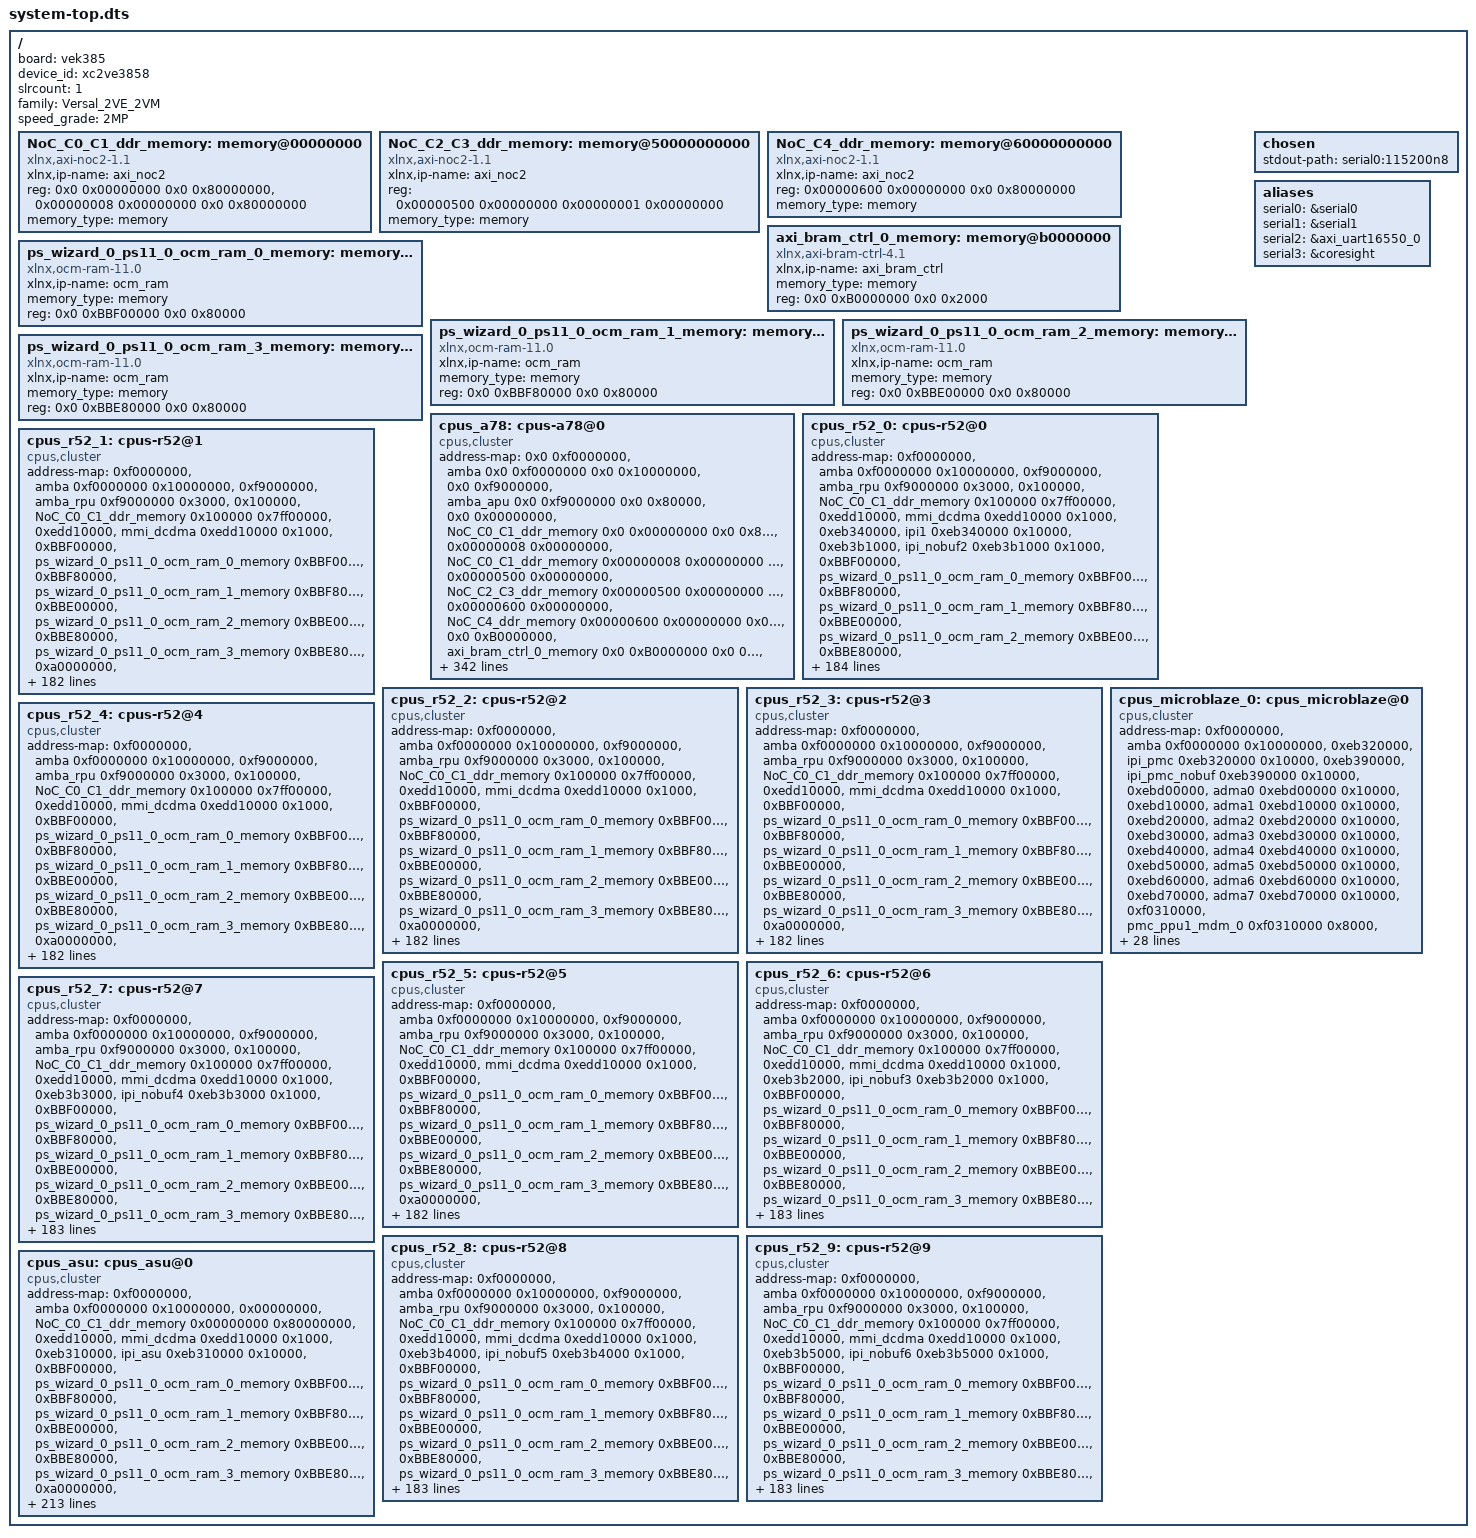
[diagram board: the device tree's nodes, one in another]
/dts-v1/;
#include "versal2.dtsi"
#include "versal2-clk-ccf.dtsi"
#include "pl.dtsi"
#include "pcw.dtsi"
/ {
	board = "vek385";
	device_id = "xc2ve3858";
	slrcount = <1>;
	family = "Versal_2VE_2VM";
	speed_grade = "2MP";
	NoC_C0_C1_ddr_memory: memory@00000000 {
		compatible = "xlnx,axi-noc2-1.1";
		xlnx,ip-name = "axi_noc2";
		device_type = "memory";
		reg = <0x0 0x00000000 0x0 0x80000000>, <0x00000008 0x00000000 0x0 0x80000000>;
		memory_type = "memory";
	};
	NoC_C2_C3_ddr_memory: memory@50000000000 {
		compatible = "xlnx,axi-noc2-1.1";
		xlnx,ip-name = "axi_noc2";
		device_type = "memory";
		reg = <0x00000500 0x00000000 0x00000001 0x00000000>;
		memory_type = "memory";
	};
	NoC_C4_ddr_memory: memory@60000000000 {
		compatible = "xlnx,axi-noc2-1.1";
		xlnx,ip-name = "axi_noc2";
		device_type = "memory";
		reg = <0x00000600 0x00000000 0x0 0x80000000>;
		memory_type = "memory";
	};
	axi_bram_ctrl_0_memory: memory@b0000000 {
		compatible = "xlnx,axi-bram-ctrl-4.1";
		xlnx,ip-name = "axi_bram_ctrl";
		device_type = "memory";
		memory_type = "memory";
		reg = <0x0 0xB0000000 0x0 0x2000>;
	};
	ps_wizard_0_ps11_0_ocm_ram_0_memory: memory@BBF00000 {
		compatible = "xlnx,ocm-ram-11.0" , "mmio-sram";
		xlnx,ip-name = "ocm_ram";
		device_type = "memory";
		memory_type = "memory";
		reg = <0x0 0xBBF00000 0x0 0x80000>;
	};
	ps_wizard_0_ps11_0_ocm_ram_1_memory: memory@BBF80000 {
		compatible = "xlnx,ocm-ram-11.0" , "mmio-sram";
		xlnx,ip-name = "ocm_ram";
		device_type = "memory";
		memory_type = "memory";
		reg = <0x0 0xBBF80000 0x0 0x80000>;
	};
	ps_wizard_0_ps11_0_ocm_ram_2_memory: memory@BBE00000 {
		compatible = "xlnx,ocm-ram-11.0" , "mmio-sram";
		xlnx,ip-name = "ocm_ram";
		device_type = "memory";
		memory_type = "memory";
		reg = <0x0 0xBBE00000 0x0 0x80000>;
	};
	ps_wizard_0_ps11_0_ocm_ram_3_memory: memory@BBE80000 {
		compatible = "xlnx,ocm-ram-11.0" , "mmio-sram";
		xlnx,ip-name = "ocm_ram";
		device_type = "memory";
		memory_type = "memory";
		reg = <0x0 0xBBE80000 0x0 0x80000>;
	};
	chosen {
		stdout-path = "serial0:115200n8";
	};
	aliases {
		serial0 = &serial0;
		serial1 = &serial1;
		serial2 = &axi_uart16550_0;
		serial3 = &coresight;
	};
	cpus_a78: cpus-a78@0 {
		compatible = "cpus,cluster";
		address-map = <0x0 0xf0000000 &amba 0x0 0xf0000000 0x0 0x10000000>, 
			      <0x0 0xf9000000 &amba_apu 0x0 0xf9000000 0x0 0x80000>, 
			      <0x0 0x00000000 &NoC_C0_C1_ddr_memory 0x0 0x00000000 0x0 0x80000000>, 
			      <0x00000008 0x00000000 &NoC_C0_C1_ddr_memory 0x00000008 0x00000000 0x0 0x80000000>, 
			      <0x00000500 0x00000000 &NoC_C2_C3_ddr_memory 0x00000500 0x00000000 0x00000001 0x00000000>, 
			      <0x00000600 0x00000000 &NoC_C4_ddr_memory 0x00000600 0x00000000 0x0 0x80000000>, 
			      <0x0 0xB0000000 &axi_bram_ctrl_0_memory 0x0 0xB0000000 0x0 0x2000>, 
			      <0x0 0xB0000000 &axi_bram_ctrl_0 0x0 0xB0000000 0x0 0x2000>, 
			      <0x0 0xedd10000 &mmi_dcdma 0x0 0xedd10000 0x0 0x1000>, 
			      <0x0 0xeb330000 &ipi0 0x0 0xeb330000 0x0 0x10000>, 
			      <0x0 0xeb3b0000 &ipi_nobuf1 0x0 0xeb3b0000 0x0 0x1000>, 
			      <0x0 0xeb350000 &ipi2 0x0 0xeb350000 0x0 0x10000>, 
			      <0x0 0xeb360000 &ipi3 0x0 0xeb360000 0x0 0x10000>, 
			      <0x0 0xeb370000 &ipi4 0x0 0xeb370000 0x0 0x10000>, 
			      <0x0 0xeb380000 &ipi5 0x0 0xeb380000 0x0 0x10000>, 
			      <0x0 0xeb3a0000 &ipi6 0x0 0xeb3a0000 0x0 0x10000>, 
			      <0x0 0xBBF00000 &ps_wizard_0_ps11_0_ocm_ram_0_memory 0x0 0xBBF00000 0x0 0x80000>, 
			      <0x0 0xBBF80000 &ps_wizard_0_ps11_0_ocm_ram_1_memory 0x0 0xBBF80000 0x0 0x80000>, 
			      <0x0 0xBBE00000 &ps_wizard_0_ps11_0_ocm_ram_2_memory 0x0 0xBBE00000 0x0 0x80000>, 
			      <0x0 0xBBE80000 &ps_wizard_0_ps11_0_ocm_ram_3_memory 0x0 0xBBE80000 0x0 0x80000>, 
			      <0x0 0xa0000000 &ps_wizard_0_ps11_0_noc_pcie_0 0x0 0xa0000000 0x0 0x10000000>, 
			      <0x0 0xa0000000 &ps_wizard_0_mmi_0_mmi_pcie_region_0 0x0 0xa0000000 0x0 0x10000000>, 
			      <0x0 0xb2000000 &axi_uart16550_0 0x0 0xb2000000 0x0 0x10000>, 
			      <0x0 0xb2010000 &pl_mmi_clk_wiz 0x0 0xb2010000 0x0 0x10000>, 
			      <0x0 0xb2020000 &axi_gpio_0 0x0 0xb2020000 0x0 0x10000>, 
			      <0x0 0xb2030000 &axi_gpio_1 0x0 0xb2030000 0x0 0x10000>, 
			      <0x0 0xb2040000 &axi_gpio_2 0x0 0xb2040000 0x0 0x10000>, 
			      <0x0 0xb2050000 &board_misc_gpios_board_misc_i2c1_alt_in 0x0 0xb2050000 0x0 0x10000>, 
			      <0x0 0xb2060000 &board_misc_gpios_board_misc_pcie_ep 0x0 0xb2060000 0x0 0x10000>, 
			      <0x0 0xb2070000 &board_misc_gpios_board_misc_pl_io_l16p 0x0 0xb2070000 0x0 0x10000>, 
			      <0x0 0xb2080000 &board_misc_gpios_board_misc_sc_gpio_in 0x0 0xb2080000 0x0 0x10000>, 
			      <0x0 0xb2090000 &board_misc_gpios_board_misc_sc_gpio_out 0x0 0xb2090000 0x0 0x10000>, 
			      <0x0 0xe2000000 &gic_a78 0x0 0xe2000000 0x0 0x400000>, 
			      <0x0 0xea460000 &ps_wizard_0_ps11_0_lpd_systmr_read 0x0 0xea460000 0x0 0x10000>, 
			      <0x0 0xea470000 &ps_wizard_0_ps11_0_lpd_systmr_ctrl 0x0 0xea470000 0x0 0x10000>, 
			      <0x0 0xeaa00000 &ps_wizard_0_ps11_0_ocm_ctrl_3 0x0 0xeaa00000 0x0 0x10000>, 
			      <0x0 0xeb400000 &ps_wizard_0_ps11_0_ocm_xmpu_0 0x0 0xeb400000 0x0 0x10000>, 
			      <0x0 0xeb410000 &ps_wizard_0_ps11_0_lpd_slcr_0 0x0 0xeb410000 0x0 0x100000>, 
			      <0x0 0xeb510000 &ps_wizard_0_ps11_0_lpd_slcr_secure_0 0x0 0xeb510000 0x0 0x40000>, 
			      <0x0 0xeb580000 &ps_wizard_0_ps11_0_rpu_a 0x0 0xeb580000 0x0 0x8000>, 
			      <0x0 0xeb590000 &ps_wizard_0_ps11_0_rpu_b 0x0 0xeb590000 0x0 0x8000>, 
			      <0x0 0xeb5d0000 &ps_wizard_0_ps11_0_ocm_ctrl_0 0x0 0xeb5d0000 0x0 0x10000>, 
			      <0x0 0xeb5e0000 &ps_wizard_0_ps11_0_crl_0 0x0 0xeb5e0000 0x0 0x300000>, 
			      <0x0 0xeb960000 &ps_wizard_0_ps11_0_ocm_ctrl_1 0x0 0xeb960000 0x0 0x10000>, 
			      <0x0 0xeb980000 &ps_wizard_0_ps11_0_ocm_xmpu_1 0x0 0xeb980000 0x0 0x10000>, 
			      <0x0 0xeb990000 &ps_wizard_0_ps11_0_lpd_xppu_0 0x0 0xeb990000 0x0 0x10000>, 
			      <0x0 0xeb9b0000 &ps_wizard_0_ps11_0_lpd_afi_0 0x0 0xeb9b0000 0x0 0x10000>, 
			      <0x0 0xeb9d0000 &ps_wizard_0_ps11_0_ocm_ctrl_2 0x0 0xeb9d0000 0x0 0x10000>, 
			      <0x0 0xeba00000 &r52_0a_atcm_global 0x0 0xeba00000 0x0 0x10000>, 
			      <0x0 0xeba10000 &r52_0a_btcm_global 0x0 0xeba10000 0x0 0x8000>, 
			      <0x0 0xeba20000 &r52_0a_ctcm_global 0x0 0xeba20000 0x0 0x8000>, 
			      <0x0 0xeba40000 &r52_1a_atcm_global 0x0 0xeba40000 0x0 0x10000>, 
			      <0x0 0xeba50000 &r52_1a_btcm_global 0x0 0xeba50000 0x0 0x8000>, 
			      <0x0 0xeba60000 &r52_1a_ctcm_global 0x0 0xeba60000 0x0 0x8000>, 
			      <0x0 0xeba80000 &r52_0b_atcm_global 0x0 0xeba80000 0x0 0x10000>, 
			      <0x0 0xeba90000 &r52_0b_btcm_global 0x0 0xeba90000 0x0 0x8000>, 
			      <0x0 0xebaa0000 &r52_0b_ctcm_global 0x0 0xebaa0000 0x0 0x8000>, 
			      <0x0 0xebac0000 &r52_1b_atcm_global 0x0 0xebac0000 0x0 0x10000>, 
			      <0x0 0xebad0000 &r52_1b_btcm_global 0x0 0xebad0000 0x0 0x8000>, 
			      <0x0 0xebae0000 &r52_1b_ctcm_global 0x0 0xebae0000 0x0 0x8000>, 
			      <0x0 0xebb00000 &r52_0c_atcm_global 0x0 0xebb00000 0x0 0x10000>, 
			      <0x0 0xebb10000 &r52_0c_btcm_global 0x0 0xebb10000 0x0 0x8000>, 
			      <0x0 0xebb20000 &r52_0c_ctcm_global 0x0 0xebb20000 0x0 0x8000>, 
			      <0x0 0xebb40000 &r52_1c_atcm_global 0x0 0xebb40000 0x0 0x10000>, 
			      <0x0 0xebb50000 &r52_1c_btcm_global 0x0 0xebb50000 0x0 0x8000>, 
			      <0x0 0xebb60000 &r52_1c_ctcm_global 0x0 0xebb60000 0x0 0x8000>, 
			      <0x0 0xebb80000 &r52_0d_atcm_global 0x0 0xebb80000 0x0 0x10000>, 
			      <0x0 0xebb90000 &r52_0d_btcm_global 0x0 0xebb90000 0x0 0x8000>, 
			      <0x0 0xebba0000 &r52_0d_ctcm_global 0x0 0xebba0000 0x0 0x8000>, 
			      <0x0 0xebbc0000 &r52_1d_atcm_global 0x0 0xebbc0000 0x0 0x10000>, 
			      <0x0 0xebbd0000 &r52_1d_btcm_global 0x0 0xebbd0000 0x0 0x8000>, 
			      <0x0 0xebbe0000 &r52_1d_ctcm_global 0x0 0xebbe0000 0x0 0x8000>, 
			      <0x0 0xebc00000 &r52_0e_atcm_global 0x0 0xebc00000 0x0 0x10000>, 
			      <0x0 0xebc10000 &r52_0e_btcm_global 0x0 0xebc10000 0x0 0x8000>, 
			      <0x0 0xebc20000 &r52_0e_ctcm_global 0x0 0xebc20000 0x0 0x8000>, 
			      <0x0 0xebc40000 &r52_1e_atcm_global 0x0 0xebc40000 0x0 0x10000>, 
			      <0x0 0xebc50000 &r52_1e_btcm_global 0x0 0xebc50000 0x0 0x8000>, 
			      <0x0 0xebc60000 &r52_1e_ctcm_global 0x0 0xebc60000 0x0 0x8000>, 
			      <0x0 0xebd00000 &adma0 0x0 0xebd00000 0x0 0x10000>, 
			      <0x0 0xebd10000 &adma1 0x0 0xebd10000 0x0 0x10000>, 
			      <0x0 0xebd20000 &adma2 0x0 0xebd20000 0x0 0x10000>, 
			      <0x0 0xebd30000 &adma3 0x0 0xebd30000 0x0 0x10000>, 
			      <0x0 0xebd40000 &adma4 0x0 0xebd40000 0x0 0x10000>, 
			      <0x0 0xebd50000 &adma5 0x0 0xebd50000 0x0 0x10000>, 
			      <0x0 0xebd60000 &adma6 0x0 0xebd60000 0x0 0x10000>, 
			      <0x0 0xebd70000 &adma7 0x0 0xebd70000 0x0 0x10000>, 
			      <0x0 0xebe8c000 &asu_dma0 0x0 0xebe8c000 0x0 0x1000>, 
			      <0x0 0xec200000 &ps_wizard_0_ps11_0_crf_0 0x0 0xec200000 0x0 0x100000>, 
			      <0x0 0xec810000 &ps_wizard_0_ps11_0_fpd_slv_asild_xmpu_0 0x0 0xec810000 0x0 0x10000>, 
			      <0x0 0xec820000 &ps_wizard_0_ps11_0_fpd_slv_asilb_xmpu_0 0x0 0xec820000 0x0 0x10000>, 
			      <0x0 0xec880000 &ps_wizard_0_ps11_0_fpd_afi_0 0x0 0xec880000 0x0 0x10000>, 
			      <0x0 0xec890000 &ps_wizard_0_ps11_0_fpd_afi_1 0x0 0xec890000 0x0 0x10000>, 
			      <0x0 0xec8a0000 &ps_wizard_0_ps11_0_fpd_afi_2 0x0 0xec8a0000 0x0 0x10000>, 
			      <0x0 0xec8b0000 &ps_wizard_0_ps11_0_fpd_afi_3 0x0 0xec8b0000 0x0 0x10000>, 
			      <0x0 0xec8c0000 &ps_wizard_0_ps11_0_fpd_slcr_0 0x0 0xec8c0000 0x0 0x10000>, 
			      <0x0 0xec8e0000 &ps_wizard_0_ps11_0_fpd_slcr_secure_0 0x0 0xec8e0000 0x0 0x10000>, 
			      <0x0 0xec910000 &ps_wizard_0_ps11_0_fpd_systmr_read 0x0 0xec910000 0x0 0x10000>, 
			      <0x0 0xec920000 &ps_wizard_0_ps11_0_fpd_systmr_ctrl 0x0 0xec920000 0x0 0x10000>, 
			      <0x0 0xecc00000 &ps_wizard_0_ps11_0_apu_0 0x0 0xecc00000 0x0 0x10000>, 
			      <0x0 0xecd00000 &ps_wizard_0_ps11_0_apu_1 0x0 0xecd00000 0x0 0x10000>, 
			      <0x0 0xece00000 &ps_wizard_0_ps11_0_apu_2 0x0 0xece00000 0x0 0x10000>, 
			      <0x0 0xecf00000 &ps_wizard_0_ps11_0_apu_3 0x0 0xecf00000 0x0 0x10000>, 
			      <0x0 0xed000000 &gpu 0x0 0xed000000 0x0 0x800000>, 
			      <0x0 0xed800000 &ps_wizard_0_mmi_0_mmi_pcie0 0x0 0xed800000 0x0 0x80000>, 
			      <0x0 0xed900000 &ps_wizard_0_mmi_0_mmi_gtyp_cfg 0x0 0xed900000 0x0 0x20000>, 
			      <0x0 0xed920000 &mmi_10gbe 0x0 0xed920000 0x0 0x10000>, 
			      <0x0 0xed930000 &ps_wizard_0_mmi_0_mmi_pipe_gem_slcr 0x0 0xed930000 0x0 0x1000>, 
			      <0x0 0xed931000 &mdb_pcie0 0x0 0xed931000 0x0 0x8000>, 
			      <0x0 0xeda00000 &ps_wizard_0_mmi_0_mmi_common 0x0 0xeda00000 0x0 0x300000>, 
			      <0x0 0xedd00000 &mmi_dc 0x0 0xedd00000 0x0 0x10000>, 
			      <0x0 0xedd10000 &ps_wizard_0_mmi_0_mmi_dpdma 0x0 0xedd10000 0x0 0x10000>, 
			      <0x0 0xede00000 &mmi_dptx 0x0 0xede00000 0x0 0x40000>, 
			      <0x0 0xede40000 &ps_wizard_0_mmi_0_mmi_usb3phy_crpara 0x0 0xede40000 0x0 0x40000>, 
			      <0x0 0xede80000 &ps_wizard_0_mmi_0_mmi_trng 0x0 0xede80000 0x0 0x10000>, 
			      <0x0 0xede90000 &ps_wizard_0_mmi_0_mmi_udh_pll 0x0 0xede90000 0x0 0x10000>, 
			      <0x0 0xedea0000 &ps_wizard_0_mmi_0_mmi_udh_slcr 0x0 0xedea0000 0x0 0x10000>, 
			      <0x0 0xedeb0000 &ps_wizard_0_mmi_0_mmi_hdcp 0x0 0xedeb0000 0x0 0x8000>, 
			      <0x0 0xedeb8000 &ps_wizard_0_mmi_0_mmi_usb3phy_tca 0x0 0xedeb8000 0x0 0x4000>, 
			      <0x0 0xedebc000 &ps_wizard_0_mmi_0_mmi_usb2phy 0x0 0xedebc000 0x0 0x4000>, 
			      <0x0 0xedec0000 &mmi_dwc3 0x0 0xedec0000 0x0 0x130000>, 
			      <0x0 0xf0310000 &pmc_ppu1_mdm_0 0x0 0xf0310000 0x0 0x8000>, 
			      <0x0 0xf0800000 &coresight 0x0 0xf0800000 0x0 0x4000>, 
			      <0x0 0xf08f0000 &ps_wizard_0_ps11_0_coresight_lpd_atm 0x0 0xf08f0000 0x0 0xf000>, 
			      <0x0 0xf0c40000 &ps_wizard_0_ps11_0_coresight_fpd_stm 0x0 0xf0c40000 0x0 0x4000>, 
			      <0x0 0xf1010000 &ospi 0x0 0xf1010000 0x0 0x10000>, 
			      <0x0 0xf1020000 &gpio1 0x0 0xf1020000 0x0 0x10000>, 
			      <0x0 0xf10a0000 &ps_wizard_0_ps11_0_pmc_ufs_0 0x0 0xf10a0000 0x0 0x10000>, 
			      <0x0 0xf10b0000 &ufshc 0x0 0xf10b0000 0x0 0x10000>, 
			      <0x0 0xf1110000 &ps_wizard_0_ps11_0_pmc_global_0 0x0 0xf1110000 0x0 0x50000>, 
			      <0x0 0xf11c0000 &dma0 0x0 0xf11c0000 0x0 0x10000>, 
			      <0x0 0xf11d0000 &dma1 0x0 0xf11d0000 0x0 0x10000>, 
			      <0x0 0xf11e0000 &ps_wizard_0_ps11_0_pmc_aes 0x0 0xf11e0000 0x0 0x10000>, 
			      <0x0 0xf11f0000 &ps_wizard_0_ps11_0_pmc_bbram_ctrl 0x0 0xf11f0000 0x0 0x10000>, 
			      <0x0 0xf1200000 &ps_wizard_0_ps11_0_pmc_rsa 0x0 0xf1200000 0x0 0x10000>, 
			      <0x0 0xf1210000 &ps_wizard_0_ps11_0_pmc_sha3 0x0 0xf1210000 0x0 0x10000>, 
			      <0x0 0xf1220000 &ps_wizard_0_ps11_0_pmc_slave_boot 0x0 0xf1220000 0x0 0x10000>, 
			      <0x0 0xf1220000 &ps_wizard_0_mmi_0_pmc_slave_boot 0x0 0xf1220000 0x0 0x10000>, 
			      <0x0 0xf1230000 &pmc_trng 0x0 0xf1230000 0x0 0x10000>, 
			      <0x0 0xf1240000 &ps_wizard_0_ps11_0_pmc_efuse_ctrl 0x0 0xf1240000 0x0 0x10000>, 
			      <0x0 0xf1250000 &ps_wizard_0_ps11_0_pmc_efuse_cache 0x0 0xf1250000 0x0 0x10000>, 
			      <0x0 0xf1260000 &ps_wizard_0_ps11_0_crp_0 0x0 0xf1260000 0x0 0x10000>, 
			      <0x0 0xf1270000 &sysmon0 0x0 0xf1270000 0x0 0x30000>, 
			      <0x0 0xf12a0000 &rtc 0x0 0xf12a0000 0x0 0x10000>, 
			      <0x0 0xf12b0000 &pmc_cfu_apb_0 0x0 0xf12b0000 0x0 0x10000>, 
			      <0x0 0xf12d0000 &pmc_cfi_cframe_0 0x0 0xf12d0000 0x0 0x1000>, 
			      <0x0 0xf12f0000 &ps_wizard_0_ps11_0_pmc_xmpu_0 0x0 0xf12f0000 0x0 0x10000>, 
			      <0x0 0xf1300000 &ps_wizard_0_ps11_0_pmc_xppu_npi_0 0x0 0xf1300000 0x0 0x10000>, 
			      <0x0 0xf1310000 &ps_wizard_0_ps11_0_pmc_xppu_0 0x0 0xf1310000 0x0 0x10000>, 
			      <0x0 0xf1800000 &ps_wizard_0_ps11_0_pmc_sha2 0x0 0xf1800000 0x0 0x10000>, 
			      <0x0 0xf1920000 &serial0 0x0 0xf1920000 0x0 0x10000>, 
			      <0x0 0xf1930000 &serial1 0x0 0xf1930000 0x0 0x10000>, 
			      <0x0 0xf1940000 &i2c0 0x0 0xf1940000 0x0 0x10000>, 
			      <0x0 0xf1950000 &i2c1 0x0 0xf1950000 0x0 0x10000>, 
			      <0x0 0xf19e0000 &can0 0x0 0xf19e0000 0x0 0x10000>, 
			      <0x0 0xf19f0000 &can1 0x0 0xf19f0000 0x0 0x10000>, 
			      <0x0 0xf1a00000 &can2 0x0 0xf1a00000 0x0 0x10000>, 
			      <0x0 0xf1a10000 &can3 0x0 0xf1a10000 0x0 0x10000>, 
			      <0x0 0xf1a20000 &ps_wizard_0_ps11_0_lpd_iou_slcr_0 0x0 0xf1a20000 0x0 0x20000>, 
			      <0x0 0xf1a40000 &ps_wizard_0_ps11_0_lpd_iou_secure_slcr_0 0x0 0xf1a40000 0x0 0x10000>, 
			      <0x0 0xf1a50000 &gpio0 0x0 0xf1a50000 0x0 0x10000>, 
			      <0x0 0xf1a60000 &gem0 0x0 0xf1a60000 0x0 0x10000>, 
			      <0x0 0xf1c00000 &dwc3_1 0x0 0xf1c00000 0x0 0x100000>, 
			      <0x0 0xf1e60000 &ttc0 0x0 0xf1e60000 0x0 0x10000>, 
			      <0x0 0xf1e70000 &ttc1 0x0 0xf1e70000 0x0 0x10000>, 
			      <0x0 0xf1e80000 &ttc2 0x0 0xf1e80000 0x0 0x10000>, 
			      <0x0 0xf1e90000 &ttc3 0x0 0xf1e90000 0x0 0x10000>, 
			      <0x0 0xf1ea0000 &ttc4 0x0 0xf1ea0000 0x0 0x10000>, 
			      <0x0 0xf1eb0000 &ttc5 0x0 0xf1eb0000 0x0 0x10000>, 
			      <0x0 0xf1ec0000 &ttc6 0x0 0xf1ec0000 0x0 0x10000>, 
			      <0x0 0xf1ed0000 &ttc7 0x0 0xf1ed0000 0x0 0x10000>, 
			      <0x0 0xf1ef0000 &usb1 0x0 0xf1ef0000 0x0 0x10000>, 
			      <0x0 0xf2100000 &ps_wizard_0_ps11_0_pmc_slave_boot_stream 0x0 0xf2100000 0x0 0x10000>, 
			      <0x0 0xf2100000 &ps_wizard_0_mmi_0_pmc_slave_boot_stream 0x0 0xf2100000 0x0 0x10000>, 
			      <0x0 0xf6000000 &ps_wizard_0_ps11_0_pmc_ram_npi 0x0 0xf6000000 0x0 0x2000000>, 
			      <0x0 0xf8000000 &ps_wizard_0_ps11_0_fpd_cmn 0x0 0xf8000000 0x0 0x4000000>, 
			      <0x00000200 0x00000000 &ai_engine_0 0x00000200 0x00000000 0x00000001 0x00000000>, 
			      <0x00001000 0x00000000 &ps_wizard_0_ps11_0_cpm_cdx_dpu_high 0x00001000 0x00000000 0x00000800 0x00000000>, 
			      <0x00001000 0x00000000 &ps_wizard_0_mmi_0_cpm_cdx_dpu_high 0x00001000 0x00000000 0x00000800 0x00000000>;
		#ranges-address-cells = <0x2>;
		#ranges-size-cells = <0x2>;
	};
	cpus_r52_0: cpus-r52@0 {
		compatible = "cpus,cluster";
		address-map = <0xf0000000 &amba 0xf0000000 0x10000000>, 
			      <0xf9000000 &amba_rpu 0xf9000000 0x3000>, 
			      <0x100000 &NoC_C0_C1_ddr_memory 0x100000 0x7ff00000>, 
			      <0xedd10000 &mmi_dcdma 0xedd10000 0x1000>, 
			      <0xeb340000 &ipi1 0xeb340000 0x10000>, 
			      <0xeb3b1000 &ipi_nobuf2 0xeb3b1000 0x1000>, 
			      <0xBBF00000 &ps_wizard_0_ps11_0_ocm_ram_0_memory 0xBBF00000 0x80000>, 
			      <0xBBF80000 &ps_wizard_0_ps11_0_ocm_ram_1_memory 0xBBF80000 0x80000>, 
			      <0xBBE00000 &ps_wizard_0_ps11_0_ocm_ram_2_memory 0xBBE00000 0x80000>, 
			      <0xBBE80000 &ps_wizard_0_ps11_0_ocm_ram_3_memory 0xBBE80000 0x80000>, 
			      <0xa0000000 &ps_wizard_0_mmi_0_mmi_pcie_region_0 0xa0000000 0x10000000>, 
			      <0xea460000 &ps_wizard_0_ps11_0_lpd_systmr_read 0xea460000 0x10000>, 
			      <0xea470000 &ps_wizard_0_ps11_0_lpd_systmr_ctrl 0xea470000 0x10000>, 
			      <0xeaa00000 &ps_wizard_0_ps11_0_ocm_ctrl_3 0xeaa00000 0x10000>, 
			      <0xeb400000 &ps_wizard_0_ps11_0_ocm_xmpu_0 0xeb400000 0x10000>, 
			      <0xeb410000 &ps_wizard_0_ps11_0_lpd_slcr_0 0xeb410000 0x100000>, 
			      <0xeb510000 &ps_wizard_0_ps11_0_lpd_slcr_secure_0 0xeb510000 0x40000>, 
			      <0xeb580000 &ps_wizard_0_ps11_0_rpu_a 0xeb580000 0x8000>, 
			      <0xeb590000 &ps_wizard_0_ps11_0_rpu_b 0xeb590000 0x8000>, 
			      <0xeb5d0000 &ps_wizard_0_ps11_0_ocm_ctrl_0 0xeb5d0000 0x10000>, 
			      <0xeb5e0000 &ps_wizard_0_ps11_0_crl_0 0xeb5e0000 0x300000>, 
			      <0xeb960000 &ps_wizard_0_ps11_0_ocm_ctrl_1 0xeb960000 0x10000>, 
			      <0xeb980000 &ps_wizard_0_ps11_0_ocm_xmpu_1 0xeb980000 0x10000>, 
			      <0xeb990000 &ps_wizard_0_ps11_0_lpd_xppu_0 0xeb990000 0x10000>, 
			      <0xeb9b0000 &ps_wizard_0_ps11_0_lpd_afi_0 0xeb9b0000 0x10000>, 
			      <0xeb9d0000 &ps_wizard_0_ps11_0_ocm_ctrl_2 0xeb9d0000 0x10000>, 
			      <0xebd00000 &adma0 0xebd00000 0x10000>, 
			      <0xebd10000 &adma1 0xebd10000 0x10000>, 
			      <0xebd20000 &adma2 0xebd20000 0x10000>, 
			      <0xebd30000 &adma3 0xebd30000 0x10000>, 
			      <0xebd40000 &adma4 0xebd40000 0x10000>, 
			      <0xebd50000 &adma5 0xebd50000 0x10000>, 
			      <0xebd60000 &adma6 0xebd60000 0x10000>, 
			      <0xebd70000 &adma7 0xebd70000 0x10000>, 
			      <0xebe8c000 &asu_dma0 0xebe8c000 0x1000>, 
			      <0xec200000 &ps_wizard_0_ps11_0_crf_0 0xec200000 0x100000>, 
			      <0xec810000 &ps_wizard_0_ps11_0_fpd_slv_asild_xmpu_0 0xec810000 0x10000>, 
			      <0xec820000 &ps_wizard_0_ps11_0_fpd_slv_asilb_xmpu_0 0xec820000 0x10000>, 
			      <0xec880000 &ps_wizard_0_ps11_0_fpd_afi_0 0xec880000 0x10000>, 
			      <0xec890000 &ps_wizard_0_ps11_0_fpd_afi_1 0xec890000 0x10000>, 
			      <0xec8a0000 &ps_wizard_0_ps11_0_fpd_afi_2 0xec8a0000 0x10000>, 
			      <0xec8b0000 &ps_wizard_0_ps11_0_fpd_afi_3 0xec8b0000 0x10000>, 
			      <0xec8c0000 &ps_wizard_0_ps11_0_fpd_slcr_0 0xec8c0000 0x10000>, 
			      <0xec8e0000 &ps_wizard_0_ps11_0_fpd_slcr_secure_0 0xec8e0000 0x10000>, 
			      <0xec910000 &ps_wizard_0_ps11_0_fpd_systmr_read 0xec910000 0x10000>, 
			      <0xec920000 &ps_wizard_0_ps11_0_fpd_systmr_ctrl 0xec920000 0x10000>, 
			      <0xecc00000 &ps_wizard_0_ps11_0_apu_0 0xecc00000 0x10000>, 
			      <0xecd00000 &ps_wizard_0_ps11_0_apu_1 0xecd00000 0x10000>, 
			      <0xece00000 &ps_wizard_0_ps11_0_apu_2 0xece00000 0x10000>, 
			      <0xecf00000 &ps_wizard_0_ps11_0_apu_3 0xecf00000 0x10000>, 
			      <0xed000000 &gpu 0xed000000 0x800000>, 
			      <0xed800000 &ps_wizard_0_mmi_0_mmi_pcie0 0xed800000 0x80000>, 
			      <0xed900000 &ps_wizard_0_mmi_0_mmi_gtyp_cfg 0xed900000 0x20000>, 
			      <0xed920000 &mmi_10gbe 0xed920000 0x10000>, 
			      <0xed930000 &ps_wizard_0_mmi_0_mmi_pipe_gem_slcr 0xed930000 0x1000>, 
			      <0xed931000 &mdb_pcie0 0xed931000 0x8000>, 
			      <0xeda00000 &ps_wizard_0_mmi_0_mmi_common 0xeda00000 0x300000>, 
			      <0xedd00000 &mmi_dc 0xedd00000 0x10000>, 
			      <0xedd10000 &ps_wizard_0_mmi_0_mmi_dpdma 0xedd10000 0x10000>, 
			      <0xede00000 &mmi_dptx 0xede00000 0x40000>, 
			      <0xede40000 &ps_wizard_0_mmi_0_mmi_usb3phy_crpara 0xede40000 0x40000>, 
			      <0xede80000 &ps_wizard_0_mmi_0_mmi_trng 0xede80000 0x10000>, 
			      <0xede90000 &ps_wizard_0_mmi_0_mmi_udh_pll 0xede90000 0x10000>, 
			      <0xedea0000 &ps_wizard_0_mmi_0_mmi_udh_slcr 0xedea0000 0x10000>, 
			      <0xedeb0000 &ps_wizard_0_mmi_0_mmi_hdcp 0xedeb0000 0x8000>, 
			      <0xedeb8000 &ps_wizard_0_mmi_0_mmi_usb3phy_tca 0xedeb8000 0x4000>, 
			      <0xedebc000 &ps_wizard_0_mmi_0_mmi_usb2phy 0xedebc000 0x4000>, 
			      <0xedec0000 &mmi_dwc3 0xedec0000 0x130000>, 
			      <0xf0310000 &pmc_ppu1_mdm_0 0xf0310000 0x8000>, 
			      <0xf0800000 &coresight 0xf0800000 0x4000>, 
			      <0xf08f0000 &ps_wizard_0_ps11_0_coresight_lpd_atm 0xf08f0000 0xf000>, 
			      <0xf0c40000 &ps_wizard_0_ps11_0_coresight_fpd_stm 0xf0c40000 0x4000>, 
			      <0xf1010000 &ospi 0xf1010000 0x10000>, 
			      <0xf1020000 &gpio1 0xf1020000 0x10000>, 
			      <0xf10a0000 &ps_wizard_0_ps11_0_pmc_ufs_0 0xf10a0000 0x10000>, 
			      <0xf10b0000 &ufshc 0xf10b0000 0x10000>, 
			      <0xf1110000 &ps_wizard_0_ps11_0_pmc_global_0 0xf1110000 0x50000>, 
			      <0xf11c0000 &dma0 0xf11c0000 0x10000>, 
			      <0xf11d0000 &dma1 0xf11d0000 0x10000>, 
			      <0xf11e0000 &ps_wizard_0_ps11_0_pmc_aes 0xf11e0000 0x10000>, 
			      <0xf11f0000 &ps_wizard_0_ps11_0_pmc_bbram_ctrl 0xf11f0000 0x10000>, 
			      <0xf1200000 &ps_wizard_0_ps11_0_pmc_rsa 0xf1200000 0x10000>, 
			      <0xf1210000 &ps_wizard_0_ps11_0_pmc_sha3 0xf1210000 0x10000>, 
			      <0xf1220000 &ps_wizard_0_ps11_0_pmc_slave_boot 0xf1220000 0x10000>, 
			      <0xf1220000 &ps_wizard_0_mmi_0_pmc_slave_boot 0xf1220000 0x10000>, 
			      <0xf1230000 &pmc_trng 0xf1230000 0x10000>, 
			      <0xf1240000 &ps_wizard_0_ps11_0_pmc_efuse_ctrl 0xf1240000 0x10000>, 
			      <0xf1250000 &ps_wizard_0_ps11_0_pmc_efuse_cache 0xf1250000 0x10000>, 
			      <0xf1260000 &ps_wizard_0_ps11_0_crp_0 0xf1260000 0x10000>, 
			      <0xf1270000 &sysmon0 0xf1270000 0x30000>, 
			      <0xf12a0000 &rtc 0xf12a0000 0x10000>, 
			      <0xf12b0000 &pmc_cfu_apb_0 0xf12b0000 0x10000>, 
			      <0xf12d0000 &pmc_cfi_cframe_0 0xf12d0000 0x1000>, 
			      <0xf12f0000 &ps_wizard_0_ps11_0_pmc_xmpu_0 0xf12f0000 0x10000>, 
			      <0xf1300000 &ps_wizard_0_ps11_0_pmc_xppu_npi_0 0xf1300000 0x10000>, 
			      <0xf1310000 &ps_wizard_0_ps11_0_pmc_xppu_0 0xf1310000 0x10000>, 
			      <0xf1800000 &ps_wizard_0_ps11_0_pmc_sha2 0xf1800000 0x10000>, 
			      <0xf1920000 &serial0 0xf1920000 0x10000>, 
			      <0xf1930000 &serial1 0xf1930000 0x10000>, 
			      <0xf1940000 &i2c0 0xf1940000 0x10000>, 
			      <0xf1950000 &i2c1 0xf1950000 0x10000>, 
			      <0xf19e0000 &can0 0xf19e0000 0x10000>, 
			      <0xf19f0000 &can1 0xf19f0000 0x10000>, 
			      <0xf1a00000 &can2 0xf1a00000 0x10000>, 
			      <0xf1a10000 &can3 0xf1a10000 0x10000>, 
			      <0xf1a20000 &ps_wizard_0_ps11_0_lpd_iou_slcr_0 0xf1a20000 0x20000>, 
			      <0xf1a40000 &ps_wizard_0_ps11_0_lpd_iou_secure_slcr_0 0xf1a40000 0x10000>, 
			      <0xf1a50000 &gpio0 0xf1a50000 0x10000>, 
			      <0xf1a60000 &gem0 0xf1a60000 0x10000>, 
			      <0xf1c00000 &dwc3_1 0xf1c00000 0x100000>, 
			      <0xf1e60000 &ttc0 0xf1e60000 0x10000>, 
			      <0xf1e70000 &ttc1 0xf1e70000 0x10000>, 
			      <0xf1e80000 &ttc2 0xf1e80000 0x10000>, 
			      <0xf1e90000 &ttc3 0xf1e90000 0x10000>, 
			      <0xf1ea0000 &ttc4 0xf1ea0000 0x10000>, 
			      <0xf1eb0000 &ttc5 0xf1eb0000 0x10000>, 
			      <0xf1ec0000 &ttc6 0xf1ec0000 0x10000>, 
			      <0xf1ed0000 &ttc7 0xf1ed0000 0x10000>, 
			      <0xf1ef0000 &usb1 0xf1ef0000 0x10000>, 
			      <0xf2100000 &ps_wizard_0_ps11_0_pmc_slave_boot_stream 0xf2100000 0x10000>, 
			      <0xf2100000 &ps_wizard_0_mmi_0_pmc_slave_boot_stream 0xf2100000 0x10000>, 
			      <0xf6000000 &ps_wizard_0_ps11_0_pmc_ram_npi 0xf6000000 0x2000000>, 
			      <0xf8000000 &ps_wizard_0_ps11_0_fpd_cmn 0xf8000000 0x4000000>, 
			      <0xe2000000 &gic_r52 0xe2000000 0x10000>;
		#ranges-address-cells = <0x1>;
		#ranges-size-cells = <0x1>;
	};
	cpus_r52_1: cpus-r52@1 {
		compatible = "cpus,cluster";
		address-map = <0xf0000000 &amba 0xf0000000 0x10000000>, 
			      <0xf9000000 &amba_rpu 0xf9000000 0x3000>, 
			      <0x100000 &NoC_C0_C1_ddr_memory 0x100000 0x7ff00000>, 
			      <0xedd10000 &mmi_dcdma 0xedd10000 0x1000>, 
			      <0xBBF00000 &ps_wizard_0_ps11_0_ocm_ram_0_memory 0xBBF00000 0x80000>, 
			      <0xBBF80000 &ps_wizard_0_ps11_0_ocm_ram_1_memory 0xBBF80000 0x80000>, 
			      <0xBBE00000 &ps_wizard_0_ps11_0_ocm_ram_2_memory 0xBBE00000 0x80000>, 
			      <0xBBE80000 &ps_wizard_0_ps11_0_ocm_ram_3_memory 0xBBE80000 0x80000>, 
			      <0xa0000000 &ps_wizard_0_mmi_0_mmi_pcie_region_0 0xa0000000 0x10000000>, 
			      <0xea460000 &ps_wizard_0_ps11_0_lpd_systmr_read 0xea460000 0x10000>, 
			      <0xea470000 &ps_wizard_0_ps11_0_lpd_systmr_ctrl 0xea470000 0x10000>, 
			      <0xeaa00000 &ps_wizard_0_ps11_0_ocm_ctrl_3 0xeaa00000 0x10000>, 
			      <0xeb400000 &ps_wizard_0_ps11_0_ocm_xmpu_0 0xeb400000 0x10000>, 
			      <0xeb410000 &ps_wizard_0_ps11_0_lpd_slcr_0 0xeb410000 0x100000>, 
			      <0xeb510000 &ps_wizard_0_ps11_0_lpd_slcr_secure_0 0xeb510000 0x40000>, 
			      <0xeb580000 &ps_wizard_0_ps11_0_rpu_a 0xeb580000 0x8000>, 
			      <0xeb590000 &ps_wizard_0_ps11_0_rpu_b 0xeb590000 0x8000>, 
			      <0xeb5d0000 &ps_wizard_0_ps11_0_ocm_ctrl_0 0xeb5d0000 0x10000>, 
			      <0xeb5e0000 &ps_wizard_0_ps11_0_crl_0 0xeb5e0000 0x300000>, 
			      <0xeb960000 &ps_wizard_0_ps11_0_ocm_ctrl_1 0xeb960000 0x10000>, 
			      <0xeb980000 &ps_wizard_0_ps11_0_ocm_xmpu_1 0xeb980000 0x10000>, 
			      <0xeb990000 &ps_wizard_0_ps11_0_lpd_xppu_0 0xeb990000 0x10000>, 
			      <0xeb9b0000 &ps_wizard_0_ps11_0_lpd_afi_0 0xeb9b0000 0x10000>, 
			      <0xeb9d0000 &ps_wizard_0_ps11_0_ocm_ctrl_2 0xeb9d0000 0x10000>, 
			      <0xebd00000 &adma0 0xebd00000 0x10000>, 
			      <0xebd10000 &adma1 0xebd10000 0x10000>, 
			      <0xebd20000 &adma2 0xebd20000 0x10000>, 
			      <0xebd30000 &adma3 0xebd30000 0x10000>, 
			      <0xebd40000 &adma4 0xebd40000 0x10000>, 
			      <0xebd50000 &adma5 0xebd50000 0x10000>, 
			      <0xebd60000 &adma6 0xebd60000 0x10000>, 
			      <0xebd70000 &adma7 0xebd70000 0x10000>, 
			      <0xebe8c000 &asu_dma0 0xebe8c000 0x1000>, 
			      <0xec200000 &ps_wizard_0_ps11_0_crf_0 0xec200000 0x100000>, 
			      <0xec810000 &ps_wizard_0_ps11_0_fpd_slv_asild_xmpu_0 0xec810000 0x10000>, 
			      <0xec820000 &ps_wizard_0_ps11_0_fpd_slv_asilb_xmpu_0 0xec820000 0x10000>, 
			      <0xec880000 &ps_wizard_0_ps11_0_fpd_afi_0 0xec880000 0x10000>, 
			      <0xec890000 &ps_wizard_0_ps11_0_fpd_afi_1 0xec890000 0x10000>, 
			      <0xec8a0000 &ps_wizard_0_ps11_0_fpd_afi_2 0xec8a0000 0x10000>, 
			      <0xec8b0000 &ps_wizard_0_ps11_0_fpd_afi_3 0xec8b0000 0x10000>, 
			      <0xec8c0000 &ps_wizard_0_ps11_0_fpd_slcr_0 0xec8c0000 0x10000>, 
			      <0xec8e0000 &ps_wizard_0_ps11_0_fpd_slcr_secure_0 0xec8e0000 0x10000>, 
			      <0xec910000 &ps_wizard_0_ps11_0_fpd_systmr_read 0xec910000 0x10000>, 
			      <0xec920000 &ps_wizard_0_ps11_0_fpd_systmr_ctrl 0xec920000 0x10000>, 
			      <0xecc00000 &ps_wizard_0_ps11_0_apu_0 0xecc00000 0x10000>, 
			      <0xecd00000 &ps_wizard_0_ps11_0_apu_1 0xecd00000 0x10000>, 
			      <0xece00000 &ps_wizard_0_ps11_0_apu_2 0xece00000 0x10000>, 
			      <0xecf00000 &ps_wizard_0_ps11_0_apu_3 0xecf00000 0x10000>, 
			      <0xed000000 &gpu 0xed000000 0x800000>, 
			      <0xed800000 &ps_wizard_0_mmi_0_mmi_pcie0 0xed800000 0x80000>, 
			      <0xed900000 &ps_wizard_0_mmi_0_mmi_gtyp_cfg 0xed900000 0x20000>, 
			      <0xed920000 &mmi_10gbe 0xed920000 0x10000>, 
			      <0xed930000 &ps_wizard_0_mmi_0_mmi_pipe_gem_slcr 0xed930000 0x1000>, 
			      <0xed931000 &mdb_pcie0 0xed931000 0x8000>, 
			      <0xeda00000 &ps_wizard_0_mmi_0_mmi_common 0xeda00000 0x300000>, 
			      <0xedd00000 &mmi_dc 0xedd00000 0x10000>, 
			      <0xedd10000 &ps_wizard_0_mmi_0_mmi_dpdma 0xedd10000 0x10000>, 
			      <0xede00000 &mmi_dptx 0xede00000 0x40000>, 
			      <0xede40000 &ps_wizard_0_mmi_0_mmi_usb3phy_crpara 0xede40000 0x40000>, 
			      <0xede80000 &ps_wizard_0_mmi_0_mmi_trng 0xede80000 0x10000>, 
			      <0xede90000 &ps_wizard_0_mmi_0_mmi_udh_pll 0xede90000 0x10000>, 
			      <0xedea0000 &ps_wizard_0_mmi_0_mmi_udh_slcr 0xedea0000 0x10000>, 
			      <0xedeb0000 &ps_wizard_0_mmi_0_mmi_hdcp 0xedeb0000 0x8000>, 
			      <0xedeb8000 &ps_wizard_0_mmi_0_mmi_usb3phy_tca 0xedeb8000 0x4000>, 
			      <0xedebc000 &ps_wizard_0_mmi_0_mmi_usb2phy 0xedebc000 0x4000>, 
			      <0xedec0000 &mmi_dwc3 0xedec0000 0x130000>, 
			      <0xf0310000 &pmc_ppu1_mdm_0 0xf0310000 0x8000>, 
			      <0xf0800000 &coresight 0xf0800000 0x4000>, 
			      <0xf08f0000 &ps_wizard_0_ps11_0_coresight_lpd_atm 0xf08f0000 0xf000>, 
			      <0xf0c40000 &ps_wizard_0_ps11_0_coresight_fpd_stm 0xf0c40000 0x4000>, 
			      <0xf1010000 &ospi 0xf1010000 0x10000>, 
			      <0xf1020000 &gpio1 0xf1020000 0x10000>, 
			      <0xf10a0000 &ps_wizard_0_ps11_0_pmc_ufs_0 0xf10a0000 0x10000>, 
			      <0xf10b0000 &ufshc 0xf10b0000 0x10000>, 
			      <0xf1110000 &ps_wizard_0_ps11_0_pmc_global_0 0xf1110000 0x50000>, 
			      <0xf11c0000 &dma0 0xf11c0000 0x10000>, 
			      <0xf11d0000 &dma1 0xf11d0000 0x10000>, 
			      <0xf11e0000 &ps_wizard_0_ps11_0_pmc_aes 0xf11e0000 0x10000>, 
			      <0xf11f0000 &ps_wizard_0_ps11_0_pmc_bbram_ctrl 0xf11f0000 0x10000>, 
			      <0xf1200000 &ps_wizard_0_ps11_0_pmc_rsa 0xf1200000 0x10000>, 
			      <0xf1210000 &ps_wizard_0_ps11_0_pmc_sha3 0xf1210000 0x10000>, 
			      <0xf1220000 &ps_wizard_0_ps11_0_pmc_slave_boot 0xf1220000 0x10000>, 
			      <0xf1220000 &ps_wizard_0_mmi_0_pmc_slave_boot 0xf1220000 0x10000>, 
			      <0xf1230000 &pmc_trng 0xf1230000 0x10000>, 
			      <0xf1240000 &ps_wizard_0_ps11_0_pmc_efuse_ctrl 0xf1240000 0x10000>, 
			      <0xf1250000 &ps_wizard_0_ps11_0_pmc_efuse_cache 0xf1250000 0x10000>, 
			      <0xf1260000 &ps_wizard_0_ps11_0_crp_0 0xf1260000 0x10000>, 
			      <0xf1270000 &sysmon0 0xf1270000 0x30000>, 
			      <0xf12a0000 &rtc 0xf12a0000 0x10000>, 
			      <0xf12b0000 &pmc_cfu_apb_0 0xf12b0000 0x10000>, 
			      <0xf12d0000 &pmc_cfi_cframe_0 0xf12d0000 0x1000>, 
			      <0xf12f0000 &ps_wizard_0_ps11_0_pmc_xmpu_0 0xf12f0000 0x10000>, 
			      <0xf1300000 &ps_wizard_0_ps11_0_pmc_xppu_npi_0 0xf1300000 0x10000>, 
			      <0xf1310000 &ps_wizard_0_ps11_0_pmc_xppu_0 0xf1310000 0x10000>, 
			      <0xf1800000 &ps_wizard_0_ps11_0_pmc_sha2 0xf1800000 0x10000>, 
			      <0xf1920000 &serial0 0xf1920000 0x10000>, 
			      <0xf1930000 &serial1 0xf1930000 0x10000>, 
			      <0xf1940000 &i2c0 0xf1940000 0x10000>, 
			      <0xf1950000 &i2c1 0xf1950000 0x10000>, 
			      <0xf19e0000 &can0 0xf19e0000 0x10000>, 
			      <0xf19f0000 &can1 0xf19f0000 0x10000>, 
			      <0xf1a00000 &can2 0xf1a00000 0x10000>, 
			      <0xf1a10000 &can3 0xf1a10000 0x10000>, 
			      <0xf1a20000 &ps_wizard_0_ps11_0_lpd_iou_slcr_0 0xf1a20000 0x20000>, 
			      <0xf1a40000 &ps_wizard_0_ps11_0_lpd_iou_secure_slcr_0 0xf1a40000 0x10000>, 
			      <0xf1a50000 &gpio0 0xf1a50000 0x10000>, 
			      <0xf1a60000 &gem0 0xf1a60000 0x10000>, 
			      <0xf1c00000 &dwc3_1 0xf1c00000 0x100000>, 
			      <0xf1e60000 &ttc0 0xf1e60000 0x10000>, 
			      <0xf1e70000 &ttc1 0xf1e70000 0x10000>, 
			      <0xf1e80000 &ttc2 0xf1e80000 0x10000>, 
			      <0xf1e90000 &ttc3 0xf1e90000 0x10000>, 
			      <0xf1ea0000 &ttc4 0xf1ea0000 0x10000>, 
			      <0xf1eb0000 &ttc5 0xf1eb0000 0x10000>, 
			      <0xf1ec0000 &ttc6 0xf1ec0000 0x10000>, 
			      <0xf1ed0000 &ttc7 0xf1ed0000 0x10000>, 
			      <0xf1ef0000 &usb1 0xf1ef0000 0x10000>, 
			      <0xf2100000 &ps_wizard_0_ps11_0_pmc_slave_boot_stream 0xf2100000 0x10000>, 
			      <0xf2100000 &ps_wizard_0_mmi_0_pmc_slave_boot_stream 0xf2100000 0x10000>, 
			      <0xf6000000 &ps_wizard_0_ps11_0_pmc_ram_npi 0xf6000000 0x2000000>, 
			      <0xf8000000 &ps_wizard_0_ps11_0_fpd_cmn 0xf8000000 0x4000000>, 
			      <0xe2000000 &gic_r52 0xe2000000 0x10000>;
		#ranges-address-cells = <0x1>;
		#ranges-size-cells = <0x1>;
	};
	cpus_r52_2: cpus-r52@2 {
		compatible = "cpus,cluster";
		address-map = <0xf0000000 &amba 0xf0000000 0x10000000>, 
			      <0xf9000000 &amba_rpu 0xf9000000 0x3000>, 
			      <0x100000 &NoC_C0_C1_ddr_memory 0x100000 0x7ff00000>, 
			      <0xedd10000 &mmi_dcdma 0xedd10000 0x1000>, 
			      <0xBBF00000 &ps_wizard_0_ps11_0_ocm_ram_0_memory 0xBBF00000 0x80000>, 
			      <0xBBF80000 &ps_wizard_0_ps11_0_ocm_ram_1_memory 0xBBF80000 0x80000>, 
			      <0xBBE00000 &ps_wizard_0_ps11_0_ocm_ram_2_memory 0xBBE00000 0x80000>, 
			      <0xBBE80000 &ps_wizard_0_ps11_0_ocm_ram_3_memory 0xBBE80000 0x80000>, 
			      <0xa0000000 &ps_wizard_0_mmi_0_mmi_pcie_region_0 0xa0000000 0x10000000>, 
			      <0xea460000 &ps_wizard_0_ps11_0_lpd_systmr_read 0xea460000 0x10000>, 
			      <0xea470000 &ps_wizard_0_ps11_0_lpd_systmr_ctrl 0xea470000 0x10000>, 
			      <0xeaa00000 &ps_wizard_0_ps11_0_ocm_ctrl_3 0xeaa00000 0x10000>, 
			      <0xeb400000 &ps_wizard_0_ps11_0_ocm_xmpu_0 0xeb400000 0x10000>, 
			      <0xeb410000 &ps_wizard_0_ps11_0_lpd_slcr_0 0xeb410000 0x100000>, 
			      <0xeb510000 &ps_wizard_0_ps11_0_lpd_slcr_secure_0 0xeb510000 0x40000>, 
			      <0xeb580000 &ps_wizard_0_ps11_0_rpu_a 0xeb580000 0x8000>, 
			      <0xeb590000 &ps_wizard_0_ps11_0_rpu_b 0xeb590000 0x8000>, 
			      <0xeb5d0000 &ps_wizard_0_ps11_0_ocm_ctrl_0 0xeb5d0000 0x10000>, 
			      <0xeb5e0000 &ps_wizard_0_ps11_0_crl_0 0xeb5e0000 0x300000>, 
			      <0xeb960000 &ps_wizard_0_ps11_0_ocm_ctrl_1 0xeb960000 0x10000>, 
			      <0xeb980000 &ps_wizard_0_ps11_0_ocm_xmpu_1 0xeb980000 0x10000>, 
			      <0xeb990000 &ps_wizard_0_ps11_0_lpd_xppu_0 0xeb990000 0x10000>, 
			      <0xeb9b0000 &ps_wizard_0_ps11_0_lpd_afi_0 0xeb9b0000 0x10000>, 
			      <0xeb9d0000 &ps_wizard_0_ps11_0_ocm_ctrl_2 0xeb9d0000 0x10000>, 
			      <0xebd00000 &adma0 0xebd00000 0x10000>, 
			      <0xebd10000 &adma1 0xebd10000 0x10000>, 
			      <0xebd20000 &adma2 0xebd20000 0x10000>, 
			      <0xebd30000 &adma3 0xebd30000 0x10000>, 
			      <0xebd40000 &adma4 0xebd40000 0x10000>, 
			      <0xebd50000 &adma5 0xebd50000 0x10000>, 
			      <0xebd60000 &adma6 0xebd60000 0x10000>, 
			      <0xebd70000 &adma7 0xebd70000 0x10000>, 
			      <0xebe8c000 &asu_dma0 0xebe8c000 0x1000>, 
			      <0xec200000 &ps_wizard_0_ps11_0_crf_0 0xec200000 0x100000>, 
			      <0xec810000 &ps_wizard_0_ps11_0_fpd_slv_asild_xmpu_0 0xec810000 0x10000>, 
			      <0xec820000 &ps_wizard_0_ps11_0_fpd_slv_asilb_xmpu_0 0xec820000 0x10000>, 
			      <0xec880000 &ps_wizard_0_ps11_0_fpd_afi_0 0xec880000 0x10000>, 
			      <0xec890000 &ps_wizard_0_ps11_0_fpd_afi_1 0xec890000 0x10000>, 
			      <0xec8a0000 &ps_wizard_0_ps11_0_fpd_afi_2 0xec8a0000 0x10000>, 
			      <0xec8b0000 &ps_wizard_0_ps11_0_fpd_afi_3 0xec8b0000 0x10000>, 
			      <0xec8c0000 &ps_wizard_0_ps11_0_fpd_slcr_0 0xec8c0000 0x10000>, 
			      <0xec8e0000 &ps_wizard_0_ps11_0_fpd_slcr_secure_0 0xec8e0000 0x10000>, 
			      <0xec910000 &ps_wizard_0_ps11_0_fpd_systmr_read 0xec910000 0x10000>, 
			      <0xec920000 &ps_wizard_0_ps11_0_fpd_systmr_ctrl 0xec920000 0x10000>, 
			      <0xecc00000 &ps_wizard_0_ps11_0_apu_0 0xecc00000 0x10000>, 
			      <0xecd00000 &ps_wizard_0_ps11_0_apu_1 0xecd00000 0x10000>, 
			      <0xece00000 &ps_wizard_0_ps11_0_apu_2 0xece00000 0x10000>, 
			      <0xecf00000 &ps_wizard_0_ps11_0_apu_3 0xecf00000 0x10000>, 
			      <0xed000000 &gpu 0xed000000 0x800000>, 
			      <0xed800000 &ps_wizard_0_mmi_0_mmi_pcie0 0xed800000 0x80000>, 
			      <0xed900000 &ps_wizard_0_mmi_0_mmi_gtyp_cfg 0xed900000 0x20000>, 
			      <0xed920000 &mmi_10gbe 0xed920000 0x10000>, 
			      <0xed930000 &ps_wizard_0_mmi_0_mmi_pipe_gem_slcr 0xed930000 0x1000>, 
			      <0xed931000 &mdb_pcie0 0xed931000 0x8000>, 
			      <0xeda00000 &ps_wizard_0_mmi_0_mmi_common 0xeda00000 0x300000>, 
			      <0xedd00000 &mmi_dc 0xedd00000 0x10000>, 
			      <0xedd10000 &ps_wizard_0_mmi_0_mmi_dpdma 0xedd10000 0x10000>, 
			      <0xede00000 &mmi_dptx 0xede00000 0x40000>, 
			      <0xede40000 &ps_wizard_0_mmi_0_mmi_usb3phy_crpara 0xede40000 0x40000>, 
			      <0xede80000 &ps_wizard_0_mmi_0_mmi_trng 0xede80000 0x10000>, 
			      <0xede90000 &ps_wizard_0_mmi_0_mmi_udh_pll 0xede90000 0x10000>, 
			      <0xedea0000 &ps_wizard_0_mmi_0_mmi_udh_slcr 0xedea0000 0x10000>, 
			      <0xedeb0000 &ps_wizard_0_mmi_0_mmi_hdcp 0xedeb0000 0x8000>, 
			      <0xedeb8000 &ps_wizard_0_mmi_0_mmi_usb3phy_tca 0xedeb8000 0x4000>, 
			      <0xedebc000 &ps_wizard_0_mmi_0_mmi_usb2phy 0xedebc000 0x4000>, 
			      <0xedec0000 &mmi_dwc3 0xedec0000 0x130000>, 
			      <0xf0310000 &pmc_ppu1_mdm_0 0xf0310000 0x8000>, 
			      <0xf0800000 &coresight 0xf0800000 0x4000>, 
			      <0xf08f0000 &ps_wizard_0_ps11_0_coresight_lpd_atm 0xf08f0000 0xf000>, 
			      <0xf0c40000 &ps_wizard_0_ps11_0_coresight_fpd_stm 0xf0c40000 0x4000>, 
			      <0xf1010000 &ospi 0xf1010000 0x10000>, 
			      <0xf1020000 &gpio1 0xf1020000 0x10000>, 
			      <0xf10a0000 &ps_wizard_0_ps11_0_pmc_ufs_0 0xf10a0000 0x10000>, 
			      <0xf10b0000 &ufshc 0xf10b0000 0x10000>, 
			      <0xf1110000 &ps_wizard_0_ps11_0_pmc_global_0 0xf1110000 0x50000>, 
			      <0xf11c0000 &dma0 0xf11c0000 0x10000>, 
			      <0xf11d0000 &dma1 0xf11d0000 0x10000>, 
			      <0xf11e0000 &ps_wizard_0_ps11_0_pmc_aes 0xf11e0000 0x10000>, 
			      <0xf11f0000 &ps_wizard_0_ps11_0_pmc_bbram_ctrl 0xf11f0000 0x10000>, 
			      <0xf1200000 &ps_wizard_0_ps11_0_pmc_rsa 0xf1200000 0x10000>, 
			      <0xf1210000 &ps_wizard_0_ps11_0_pmc_sha3 0xf1210000 0x10000>, 
			      <0xf1220000 &ps_wizard_0_ps11_0_pmc_slave_boot 0xf1220000 0x10000>, 
			      <0xf1220000 &ps_wizard_0_mmi_0_pmc_slave_boot 0xf1220000 0x10000>, 
			      <0xf1230000 &pmc_trng 0xf1230000 0x10000>, 
			      <0xf1240000 &ps_wizard_0_ps11_0_pmc_efuse_ctrl 0xf1240000 0x10000>, 
			      <0xf1250000 &ps_wizard_0_ps11_0_pmc_efuse_cache 0xf1250000 0x10000>, 
			      <0xf1260000 &ps_wizard_0_ps11_0_crp_0 0xf1260000 0x10000>, 
			      <0xf1270000 &sysmon0 0xf1270000 0x30000>, 
			      <0xf12a0000 &rtc 0xf12a0000 0x10000>, 
			      <0xf12b0000 &pmc_cfu_apb_0 0xf12b0000 0x10000>, 
			      <0xf12d0000 &pmc_cfi_cframe_0 0xf12d0000 0x1000>, 
			      <0xf12f0000 &ps_wizard_0_ps11_0_pmc_xmpu_0 0xf12f0000 0x10000>, 
			      <0xf1300000 &ps_wizard_0_ps11_0_pmc_xppu_npi_0 0xf1300000 0x10000>, 
			      <0xf1310000 &ps_wizard_0_ps11_0_pmc_xppu_0 0xf1310000 0x10000>, 
			      <0xf1800000 &ps_wizard_0_ps11_0_pmc_sha2 0xf1800000 0x10000>, 
			      <0xf1920000 &serial0 0xf1920000 0x10000>, 
			      <0xf1930000 &serial1 0xf1930000 0x10000>, 
			      <0xf1940000 &i2c0 0xf1940000 0x10000>, 
			      <0xf1950000 &i2c1 0xf1950000 0x10000>, 
			      <0xf19e0000 &can0 0xf19e0000 0x10000>, 
			      <0xf19f0000 &can1 0xf19f0000 0x10000>, 
			      <0xf1a00000 &can2 0xf1a00000 0x10000>, 
			      <0xf1a10000 &can3 0xf1a10000 0x10000>, 
			      <0xf1a20000 &ps_wizard_0_ps11_0_lpd_iou_slcr_0 0xf1a20000 0x20000>, 
			      <0xf1a40000 &ps_wizard_0_ps11_0_lpd_iou_secure_slcr_0 0xf1a40000 0x10000>, 
			      <0xf1a50000 &gpio0 0xf1a50000 0x10000>, 
			      <0xf1a60000 &gem0 0xf1a60000 0x10000>, 
			      <0xf1c00000 &dwc3_1 0xf1c00000 0x100000>, 
			      <0xf1e60000 &ttc0 0xf1e60000 0x10000>, 
			      <0xf1e70000 &ttc1 0xf1e70000 0x10000>, 
			      <0xf1e80000 &ttc2 0xf1e80000 0x10000>, 
			      <0xf1e90000 &ttc3 0xf1e90000 0x10000>, 
			      <0xf1ea0000 &ttc4 0xf1ea0000 0x10000>, 
			      <0xf1eb0000 &ttc5 0xf1eb0000 0x10000>, 
			      <0xf1ec0000 &ttc6 0xf1ec0000 0x10000>, 
			      <0xf1ed0000 &ttc7 0xf1ed0000 0x10000>, 
			      <0xf1ef0000 &usb1 0xf1ef0000 0x10000>, 
			      <0xf2100000 &ps_wizard_0_ps11_0_pmc_slave_boot_stream 0xf2100000 0x10000>, 
			      <0xf2100000 &ps_wizard_0_mmi_0_pmc_slave_boot_stream 0xf2100000 0x10000>, 
			      <0xf6000000 &ps_wizard_0_ps11_0_pmc_ram_npi 0xf6000000 0x2000000>, 
			      <0xf8000000 &ps_wizard_0_ps11_0_fpd_cmn 0xf8000000 0x4000000>, 
			      <0xe2000000 &gic_r52 0xe2000000 0x10000>;
		#ranges-address-cells = <0x1>;
		#ranges-size-cells = <0x1>;
	};
	cpus_r52_3: cpus-r52@3 {
		compatible = "cpus,cluster";
		address-map = <0xf0000000 &amba 0xf0000000 0x10000000>, 
			      <0xf9000000 &amba_rpu 0xf9000000 0x3000>, 
			      <0x100000 &NoC_C0_C1_ddr_memory 0x100000 0x7ff00000>, 
			      <0xedd10000 &mmi_dcdma 0xedd10000 0x1000>, 
			      <0xBBF00000 &ps_wizard_0_ps11_0_ocm_ram_0_memory 0xBBF00000 0x80000>, 
			      <0xBBF80000 &ps_wizard_0_ps11_0_ocm_ram_1_memory 0xBBF80000 0x80000>, 
			      <0xBBE00000 &ps_wizard_0_ps11_0_ocm_ram_2_memory 0xBBE00000 0x80000>, 
			      <0xBBE80000 &ps_wizard_0_ps11_0_ocm_ram_3_memory 0xBBE80000 0x80000>, 
			      <0xa0000000 &ps_wizard_0_mmi_0_mmi_pcie_region_0 0xa0000000 0x10000000>, 
			      <0xea460000 &ps_wizard_0_ps11_0_lpd_systmr_read 0xea460000 0x10000>, 
			      <0xea470000 &ps_wizard_0_ps11_0_lpd_systmr_ctrl 0xea470000 0x10000>, 
			      <0xeaa00000 &ps_wizard_0_ps11_0_ocm_ctrl_3 0xeaa00000 0x10000>, 
			      <0xeb400000 &ps_wizard_0_ps11_0_ocm_xmpu_0 0xeb400000 0x10000>, 
			      <0xeb410000 &ps_wizard_0_ps11_0_lpd_slcr_0 0xeb410000 0x100000>, 
			      <0xeb510000 &ps_wizard_0_ps11_0_lpd_slcr_secure_0 0xeb510000 0x40000>, 
			      <0xeb580000 &ps_wizard_0_ps11_0_rpu_a 0xeb580000 0x8000>, 
			      <0xeb590000 &ps_wizard_0_ps11_0_rpu_b 0xeb590000 0x8000>, 
			      <0xeb5d0000 &ps_wizard_0_ps11_0_ocm_ctrl_0 0xeb5d0000 0x10000>, 
			      <0xeb5e0000 &ps_wizard_0_ps11_0_crl_0 0xeb5e0000 0x300000>, 
			      <0xeb960000 &ps_wizard_0_ps11_0_ocm_ctrl_1 0xeb960000 0x10000>, 
			      <0xeb980000 &ps_wizard_0_ps11_0_ocm_xmpu_1 0xeb980000 0x10000>, 
			      <0xeb990000 &ps_wizard_0_ps11_0_lpd_xppu_0 0xeb990000 0x10000>, 
			      <0xeb9b0000 &ps_wizard_0_ps11_0_lpd_afi_0 0xeb9b0000 0x10000>, 
			      <0xeb9d0000 &ps_wizard_0_ps11_0_ocm_ctrl_2 0xeb9d0000 0x10000>, 
			      <0xebd00000 &adma0 0xebd00000 0x10000>, 
			      <0xebd10000 &adma1 0xebd10000 0x10000>, 
			      <0xebd20000 &adma2 0xebd20000 0x10000>, 
			      <0xebd30000 &adma3 0xebd30000 0x10000>, 
			      <0xebd40000 &adma4 0xebd40000 0x10000>, 
			      <0xebd50000 &adma5 0xebd50000 0x10000>, 
			      <0xebd60000 &adma6 0xebd60000 0x10000>, 
			      <0xebd70000 &adma7 0xebd70000 0x10000>, 
			      <0xebe8c000 &asu_dma0 0xebe8c000 0x1000>, 
			      <0xec200000 &ps_wizard_0_ps11_0_crf_0 0xec200000 0x100000>, 
			      <0xec810000 &ps_wizard_0_ps11_0_fpd_slv_asild_xmpu_0 0xec810000 0x10000>, 
			      <0xec820000 &ps_wizard_0_ps11_0_fpd_slv_asilb_xmpu_0 0xec820000 0x10000>, 
			      <0xec880000 &ps_wizard_0_ps11_0_fpd_afi_0 0xec880000 0x10000>, 
			      <0xec890000 &ps_wizard_0_ps11_0_fpd_afi_1 0xec890000 0x10000>, 
			      <0xec8a0000 &ps_wizard_0_ps11_0_fpd_afi_2 0xec8a0000 0x10000>, 
			      <0xec8b0000 &ps_wizard_0_ps11_0_fpd_afi_3 0xec8b0000 0x10000>, 
			      <0xec8c0000 &ps_wizard_0_ps11_0_fpd_slcr_0 0xec8c0000 0x10000>, 
			      <0xec8e0000 &ps_wizard_0_ps11_0_fpd_slcr_secure_0 0xec8e0000 0x10000>, 
			      <0xec910000 &ps_wizard_0_ps11_0_fpd_systmr_read 0xec910000 0x10000>, 
			      <0xec920000 &ps_wizard_0_ps11_0_fpd_systmr_ctrl 0xec920000 0x10000>, 
			      <0xecc00000 &ps_wizard_0_ps11_0_apu_0 0xecc00000 0x10000>, 
			      <0xecd00000 &ps_wizard_0_ps11_0_apu_1 0xecd00000 0x10000>, 
			      <0xece00000 &ps_wizard_0_ps11_0_apu_2 0xece00000 0x10000>, 
			      <0xecf00000 &ps_wizard_0_ps11_0_apu_3 0xecf00000 0x10000>, 
			      <0xed000000 &gpu 0xed000000 0x800000>, 
			      <0xed800000 &ps_wizard_0_mmi_0_mmi_pcie0 0xed800000 0x80000>, 
			      <0xed900000 &ps_wizard_0_mmi_0_mmi_gtyp_cfg 0xed900000 0x20000>, 
			      <0xed920000 &mmi_10gbe 0xed920000 0x10000>, 
			      <0xed930000 &ps_wizard_0_mmi_0_mmi_pipe_gem_slcr 0xed930000 0x1000>, 
			      <0xed931000 &mdb_pcie0 0xed931000 0x8000>, 
			      <0xeda00000 &ps_wizard_0_mmi_0_mmi_common 0xeda00000 0x300000>, 
			      <0xedd00000 &mmi_dc 0xedd00000 0x10000>, 
			      <0xedd10000 &ps_wizard_0_mmi_0_mmi_dpdma 0xedd10000 0x10000>, 
			      <0xede00000 &mmi_dptx 0xede00000 0x40000>, 
			      <0xede40000 &ps_wizard_0_mmi_0_mmi_usb3phy_crpara 0xede40000 0x40000>, 
			      <0xede80000 &ps_wizard_0_mmi_0_mmi_trng 0xede80000 0x10000>, 
			      <0xede90000 &ps_wizard_0_mmi_0_mmi_udh_pll 0xede90000 0x10000>, 
			      <0xedea0000 &ps_wizard_0_mmi_0_mmi_udh_slcr 0xedea0000 0x10000>, 
			      <0xedeb0000 &ps_wizard_0_mmi_0_mmi_hdcp 0xedeb0000 0x8000>, 
			      <0xedeb8000 &ps_wizard_0_mmi_0_mmi_usb3phy_tca 0xedeb8000 0x4000>, 
			      <0xedebc000 &ps_wizard_0_mmi_0_mmi_usb2phy 0xedebc000 0x4000>, 
			      <0xedec0000 &mmi_dwc3 0xedec0000 0x130000>, 
			      <0xf0310000 &pmc_ppu1_mdm_0 0xf0310000 0x8000>, 
			      <0xf0800000 &coresight 0xf0800000 0x4000>, 
			      <0xf08f0000 &ps_wizard_0_ps11_0_coresight_lpd_atm 0xf08f0000 0xf000>, 
			      <0xf0c40000 &ps_wizard_0_ps11_0_coresight_fpd_stm 0xf0c40000 0x4000>, 
			      <0xf1010000 &ospi 0xf1010000 0x10000>, 
			      <0xf1020000 &gpio1 0xf1020000 0x10000>, 
			      <0xf10a0000 &ps_wizard_0_ps11_0_pmc_ufs_0 0xf10a0000 0x10000>, 
			      <0xf10b0000 &ufshc 0xf10b0000 0x10000>, 
			      <0xf1110000 &ps_wizard_0_ps11_0_pmc_global_0 0xf1110000 0x50000>, 
			      <0xf11c0000 &dma0 0xf11c0000 0x10000>, 
			      <0xf11d0000 &dma1 0xf11d0000 0x10000>, 
			      <0xf11e0000 &ps_wizard_0_ps11_0_pmc_aes 0xf11e0000 0x10000>, 
			      <0xf11f0000 &ps_wizard_0_ps11_0_pmc_bbram_ctrl 0xf11f0000 0x10000>, 
			      <0xf1200000 &ps_wizard_0_ps11_0_pmc_rsa 0xf1200000 0x10000>, 
			      <0xf1210000 &ps_wizard_0_ps11_0_pmc_sha3 0xf1210000 0x10000>, 
			      <0xf1220000 &ps_wizard_0_ps11_0_pmc_slave_boot 0xf1220000 0x10000>, 
			      <0xf1220000 &ps_wizard_0_mmi_0_pmc_slave_boot 0xf1220000 0x10000>, 
			      <0xf1230000 &pmc_trng 0xf1230000 0x10000>, 
			      <0xf1240000 &ps_wizard_0_ps11_0_pmc_efuse_ctrl 0xf1240000 0x10000>, 
			      <0xf1250000 &ps_wizard_0_ps11_0_pmc_efuse_cache 0xf1250000 0x10000>, 
			      <0xf1260000 &ps_wizard_0_ps11_0_crp_0 0xf1260000 0x10000>, 
			      <0xf1270000 &sysmon0 0xf1270000 0x30000>, 
			      <0xf12a0000 &rtc 0xf12a0000 0x10000>, 
			      <0xf12b0000 &pmc_cfu_apb_0 0xf12b0000 0x10000>, 
			      <0xf12d0000 &pmc_cfi_cframe_0 0xf12d0000 0x1000>, 
			      <0xf12f0000 &ps_wizard_0_ps11_0_pmc_xmpu_0 0xf12f0000 0x10000>, 
			      <0xf1300000 &ps_wizard_0_ps11_0_pmc_xppu_npi_0 0xf1300000 0x10000>, 
			      <0xf1310000 &ps_wizard_0_ps11_0_pmc_xppu_0 0xf1310000 0x10000>, 
			      <0xf1800000 &ps_wizard_0_ps11_0_pmc_sha2 0xf1800000 0x10000>, 
			      <0xf1920000 &serial0 0xf1920000 0x10000>, 
			      <0xf1930000 &serial1 0xf1930000 0x10000>, 
			      <0xf1940000 &i2c0 0xf1940000 0x10000>, 
			      <0xf1950000 &i2c1 0xf1950000 0x10000>, 
			      <0xf19e0000 &can0 0xf19e0000 0x10000>, 
			      <0xf19f0000 &can1 0xf19f0000 0x10000>, 
			      <0xf1a00000 &can2 0xf1a00000 0x10000>, 
			      <0xf1a10000 &can3 0xf1a10000 0x10000>, 
			      <0xf1a20000 &ps_wizard_0_ps11_0_lpd_iou_slcr_0 0xf1a20000 0x20000>, 
			      <0xf1a40000 &ps_wizard_0_ps11_0_lpd_iou_secure_slcr_0 0xf1a40000 0x10000>, 
			      <0xf1a50000 &gpio0 0xf1a50000 0x10000>, 
			      <0xf1a60000 &gem0 0xf1a60000 0x10000>, 
			      <0xf1c00000 &dwc3_1 0xf1c00000 0x100000>, 
			      <0xf1e60000 &ttc0 0xf1e60000 0x10000>, 
			      <0xf1e70000 &ttc1 0xf1e70000 0x10000>, 
			      <0xf1e80000 &ttc2 0xf1e80000 0x10000>, 
			      <0xf1e90000 &ttc3 0xf1e90000 0x10000>, 
			      <0xf1ea0000 &ttc4 0xf1ea0000 0x10000>, 
			      <0xf1eb0000 &ttc5 0xf1eb0000 0x10000>, 
			      <0xf1ec0000 &ttc6 0xf1ec0000 0x10000>, 
			      <0xf1ed0000 &ttc7 0xf1ed0000 0x10000>, 
			      <0xf1ef0000 &usb1 0xf1ef0000 0x10000>, 
			      <0xf2100000 &ps_wizard_0_ps11_0_pmc_slave_boot_stream 0xf2100000 0x10000>, 
			      <0xf2100000 &ps_wizard_0_mmi_0_pmc_slave_boot_stream 0xf2100000 0x10000>, 
			      <0xf6000000 &ps_wizard_0_ps11_0_pmc_ram_npi 0xf6000000 0x2000000>, 
			      <0xf8000000 &ps_wizard_0_ps11_0_fpd_cmn 0xf8000000 0x4000000>, 
			      <0xe2000000 &gic_r52 0xe2000000 0x10000>;
		#ranges-address-cells = <0x1>;
		#ranges-size-cells = <0x1>;
	};
	cpus_r52_4: cpus-r52@4 {
		compatible = "cpus,cluster";
		address-map = <0xf0000000 &amba 0xf0000000 0x10000000>, 
			      <0xf9000000 &amba_rpu 0xf9000000 0x3000>, 
			      <0x100000 &NoC_C0_C1_ddr_memory 0x100000 0x7ff00000>, 
			      <0xedd10000 &mmi_dcdma 0xedd10000 0x1000>, 
			      <0xBBF00000 &ps_wizard_0_ps11_0_ocm_ram_0_memory 0xBBF00000 0x80000>, 
			      <0xBBF80000 &ps_wizard_0_ps11_0_ocm_ram_1_memory 0xBBF80000 0x80000>, 
			      <0xBBE00000 &ps_wizard_0_ps11_0_ocm_ram_2_memory 0xBBE00000 0x80000>, 
			      <0xBBE80000 &ps_wizard_0_ps11_0_ocm_ram_3_memory 0xBBE80000 0x80000>, 
			      <0xa0000000 &ps_wizard_0_mmi_0_mmi_pcie_region_0 0xa0000000 0x10000000>, 
			      <0xea460000 &ps_wizard_0_ps11_0_lpd_systmr_read 0xea460000 0x10000>, 
			      <0xea470000 &ps_wizard_0_ps11_0_lpd_systmr_ctrl 0xea470000 0x10000>, 
			      <0xeaa00000 &ps_wizard_0_ps11_0_ocm_ctrl_3 0xeaa00000 0x10000>, 
			      <0xeb400000 &ps_wizard_0_ps11_0_ocm_xmpu_0 0xeb400000 0x10000>, 
			      <0xeb410000 &ps_wizard_0_ps11_0_lpd_slcr_0 0xeb410000 0x100000>, 
			      <0xeb510000 &ps_wizard_0_ps11_0_lpd_slcr_secure_0 0xeb510000 0x40000>, 
			      <0xeb580000 &ps_wizard_0_ps11_0_rpu_a 0xeb580000 0x8000>, 
			      <0xeb590000 &ps_wizard_0_ps11_0_rpu_b 0xeb590000 0x8000>, 
			      <0xeb5d0000 &ps_wizard_0_ps11_0_ocm_ctrl_0 0xeb5d0000 0x10000>, 
			      <0xeb5e0000 &ps_wizard_0_ps11_0_crl_0 0xeb5e0000 0x300000>, 
			      <0xeb960000 &ps_wizard_0_ps11_0_ocm_ctrl_1 0xeb960000 0x10000>, 
			      <0xeb980000 &ps_wizard_0_ps11_0_ocm_xmpu_1 0xeb980000 0x10000>, 
			      <0xeb990000 &ps_wizard_0_ps11_0_lpd_xppu_0 0xeb990000 0x10000>, 
			      <0xeb9b0000 &ps_wizard_0_ps11_0_lpd_afi_0 0xeb9b0000 0x10000>, 
			      <0xeb9d0000 &ps_wizard_0_ps11_0_ocm_ctrl_2 0xeb9d0000 0x10000>, 
			      <0xebd00000 &adma0 0xebd00000 0x10000>, 
			      <0xebd10000 &adma1 0xebd10000 0x10000>, 
			      <0xebd20000 &adma2 0xebd20000 0x10000>, 
			      <0xebd30000 &adma3 0xebd30000 0x10000>, 
			      <0xebd40000 &adma4 0xebd40000 0x10000>, 
			      <0xebd50000 &adma5 0xebd50000 0x10000>, 
			      <0xebd60000 &adma6 0xebd60000 0x10000>, 
			      <0xebd70000 &adma7 0xebd70000 0x10000>, 
			      <0xebe8c000 &asu_dma0 0xebe8c000 0x1000>, 
			      <0xec200000 &ps_wizard_0_ps11_0_crf_0 0xec200000 0x100000>, 
			      <0xec810000 &ps_wizard_0_ps11_0_fpd_slv_asild_xmpu_0 0xec810000 0x10000>, 
			      <0xec820000 &ps_wizard_0_ps11_0_fpd_slv_asilb_xmpu_0 0xec820000 0x10000>, 
			      <0xec880000 &ps_wizard_0_ps11_0_fpd_afi_0 0xec880000 0x10000>, 
			      <0xec890000 &ps_wizard_0_ps11_0_fpd_afi_1 0xec890000 0x10000>, 
			      <0xec8a0000 &ps_wizard_0_ps11_0_fpd_afi_2 0xec8a0000 0x10000>, 
			      <0xec8b0000 &ps_wizard_0_ps11_0_fpd_afi_3 0xec8b0000 0x10000>, 
			      <0xec8c0000 &ps_wizard_0_ps11_0_fpd_slcr_0 0xec8c0000 0x10000>, 
			      <0xec8e0000 &ps_wizard_0_ps11_0_fpd_slcr_secure_0 0xec8e0000 0x10000>, 
			      <0xec910000 &ps_wizard_0_ps11_0_fpd_systmr_read 0xec910000 0x10000>, 
			      <0xec920000 &ps_wizard_0_ps11_0_fpd_systmr_ctrl 0xec920000 0x10000>, 
			      <0xecc00000 &ps_wizard_0_ps11_0_apu_0 0xecc00000 0x10000>, 
			      <0xecd00000 &ps_wizard_0_ps11_0_apu_1 0xecd00000 0x10000>, 
			      <0xece00000 &ps_wizard_0_ps11_0_apu_2 0xece00000 0x10000>, 
			      <0xecf00000 &ps_wizard_0_ps11_0_apu_3 0xecf00000 0x10000>, 
			      <0xed000000 &gpu 0xed000000 0x800000>, 
			      <0xed800000 &ps_wizard_0_mmi_0_mmi_pcie0 0xed800000 0x80000>, 
			      <0xed900000 &ps_wizard_0_mmi_0_mmi_gtyp_cfg 0xed900000 0x20000>, 
			      <0xed920000 &mmi_10gbe 0xed920000 0x10000>, 
			      <0xed930000 &ps_wizard_0_mmi_0_mmi_pipe_gem_slcr 0xed930000 0x1000>, 
			      <0xed931000 &mdb_pcie0 0xed931000 0x8000>, 
			      <0xeda00000 &ps_wizard_0_mmi_0_mmi_common 0xeda00000 0x300000>, 
			      <0xedd00000 &mmi_dc 0xedd00000 0x10000>, 
			      <0xedd10000 &ps_wizard_0_mmi_0_mmi_dpdma 0xedd10000 0x10000>, 
			      <0xede00000 &mmi_dptx 0xede00000 0x40000>, 
			      <0xede40000 &ps_wizard_0_mmi_0_mmi_usb3phy_crpara 0xede40000 0x40000>, 
			      <0xede80000 &ps_wizard_0_mmi_0_mmi_trng 0xede80000 0x10000>, 
			      <0xede90000 &ps_wizard_0_mmi_0_mmi_udh_pll 0xede90000 0x10000>, 
			      <0xedea0000 &ps_wizard_0_mmi_0_mmi_udh_slcr 0xedea0000 0x10000>, 
			      <0xedeb0000 &ps_wizard_0_mmi_0_mmi_hdcp 0xedeb0000 0x8000>, 
			      <0xedeb8000 &ps_wizard_0_mmi_0_mmi_usb3phy_tca 0xedeb8000 0x4000>, 
			      <0xedebc000 &ps_wizard_0_mmi_0_mmi_usb2phy 0xedebc000 0x4000>, 
			      <0xedec0000 &mmi_dwc3 0xedec0000 0x130000>, 
			      <0xf0310000 &pmc_ppu1_mdm_0 0xf0310000 0x8000>, 
			      <0xf0800000 &coresight 0xf0800000 0x4000>, 
			      <0xf08f0000 &ps_wizard_0_ps11_0_coresight_lpd_atm 0xf08f0000 0xf000>, 
			      <0xf0c40000 &ps_wizard_0_ps11_0_coresight_fpd_stm 0xf0c40000 0x4000>, 
			      <0xf1010000 &ospi 0xf1010000 0x10000>, 
			      <0xf1020000 &gpio1 0xf1020000 0x10000>, 
			      <0xf10a0000 &ps_wizard_0_ps11_0_pmc_ufs_0 0xf10a0000 0x10000>, 
			      <0xf10b0000 &ufshc 0xf10b0000 0x10000>, 
			      <0xf1110000 &ps_wizard_0_ps11_0_pmc_global_0 0xf1110000 0x50000>, 
			      <0xf11c0000 &dma0 0xf11c0000 0x10000>, 
			      <0xf11d0000 &dma1 0xf11d0000 0x10000>, 
			      <0xf11e0000 &ps_wizard_0_ps11_0_pmc_aes 0xf11e0000 0x10000>, 
			      <0xf11f0000 &ps_wizard_0_ps11_0_pmc_bbram_ctrl 0xf11f0000 0x10000>, 
			      <0xf1200000 &ps_wizard_0_ps11_0_pmc_rsa 0xf1200000 0x10000>, 
			      <0xf1210000 &ps_wizard_0_ps11_0_pmc_sha3 0xf1210000 0x10000>, 
			      <0xf1220000 &ps_wizard_0_ps11_0_pmc_slave_boot 0xf1220000 0x10000>, 
			      <0xf1220000 &ps_wizard_0_mmi_0_pmc_slave_boot 0xf1220000 0x10000>, 
			      <0xf1230000 &pmc_trng 0xf1230000 0x10000>, 
			      <0xf1240000 &ps_wizard_0_ps11_0_pmc_efuse_ctrl 0xf1240000 0x10000>, 
			      <0xf1250000 &ps_wizard_0_ps11_0_pmc_efuse_cache 0xf1250000 0x10000>, 
			      <0xf1260000 &ps_wizard_0_ps11_0_crp_0 0xf1260000 0x10000>, 
			      <0xf1270000 &sysmon0 0xf1270000 0x30000>, 
			      <0xf12a0000 &rtc 0xf12a0000 0x10000>, 
			      <0xf12b0000 &pmc_cfu_apb_0 0xf12b0000 0x10000>, 
			      <0xf12d0000 &pmc_cfi_cframe_0 0xf12d0000 0x1000>, 
			      <0xf12f0000 &ps_wizard_0_ps11_0_pmc_xmpu_0 0xf12f0000 0x10000>, 
			      <0xf1300000 &ps_wizard_0_ps11_0_pmc_xppu_npi_0 0xf1300000 0x10000>, 
			      <0xf1310000 &ps_wizard_0_ps11_0_pmc_xppu_0 0xf1310000 0x10000>, 
			      <0xf1800000 &ps_wizard_0_ps11_0_pmc_sha2 0xf1800000 0x10000>, 
			      <0xf1920000 &serial0 0xf1920000 0x10000>, 
			      <0xf1930000 &serial1 0xf1930000 0x10000>, 
			      <0xf1940000 &i2c0 0xf1940000 0x10000>, 
			      <0xf1950000 &i2c1 0xf1950000 0x10000>, 
			      <0xf19e0000 &can0 0xf19e0000 0x10000>, 
			      <0xf19f0000 &can1 0xf19f0000 0x10000>, 
			      <0xf1a00000 &can2 0xf1a00000 0x10000>, 
			      <0xf1a10000 &can3 0xf1a10000 0x10000>, 
			      <0xf1a20000 &ps_wizard_0_ps11_0_lpd_iou_slcr_0 0xf1a20000 0x20000>, 
			      <0xf1a40000 &ps_wizard_0_ps11_0_lpd_iou_secure_slcr_0 0xf1a40000 0x10000>, 
			      <0xf1a50000 &gpio0 0xf1a50000 0x10000>, 
			      <0xf1a60000 &gem0 0xf1a60000 0x10000>, 
			      <0xf1c00000 &dwc3_1 0xf1c00000 0x100000>, 
			      <0xf1e60000 &ttc0 0xf1e60000 0x10000>, 
			      <0xf1e70000 &ttc1 0xf1e70000 0x10000>, 
			      <0xf1e80000 &ttc2 0xf1e80000 0x10000>, 
			      <0xf1e90000 &ttc3 0xf1e90000 0x10000>, 
			      <0xf1ea0000 &ttc4 0xf1ea0000 0x10000>, 
			      <0xf1eb0000 &ttc5 0xf1eb0000 0x10000>, 
			      <0xf1ec0000 &ttc6 0xf1ec0000 0x10000>, 
			      <0xf1ed0000 &ttc7 0xf1ed0000 0x10000>, 
			      <0xf1ef0000 &usb1 0xf1ef0000 0x10000>, 
			      <0xf2100000 &ps_wizard_0_ps11_0_pmc_slave_boot_stream 0xf2100000 0x10000>, 
			      <0xf2100000 &ps_wizard_0_mmi_0_pmc_slave_boot_stream 0xf2100000 0x10000>, 
			      <0xf6000000 &ps_wizard_0_ps11_0_pmc_ram_npi 0xf6000000 0x2000000>, 
			      <0xf8000000 &ps_wizard_0_ps11_0_fpd_cmn 0xf8000000 0x4000000>, 
			      <0xe2000000 &gic_r52 0xe2000000 0x10000>;
		#ranges-address-cells = <0x1>;
		#ranges-size-cells = <0x1>;
	};
	cpus_r52_5: cpus-r52@5 {
		compatible = "cpus,cluster";
		address-map = <0xf0000000 &amba 0xf0000000 0x10000000>, 
			      <0xf9000000 &amba_rpu 0xf9000000 0x3000>, 
			      <0x100000 &NoC_C0_C1_ddr_memory 0x100000 0x7ff00000>, 
			      <0xedd10000 &mmi_dcdma 0xedd10000 0x1000>, 
			      <0xBBF00000 &ps_wizard_0_ps11_0_ocm_ram_0_memory 0xBBF00000 0x80000>, 
			      <0xBBF80000 &ps_wizard_0_ps11_0_ocm_ram_1_memory 0xBBF80000 0x80000>, 
			      <0xBBE00000 &ps_wizard_0_ps11_0_ocm_ram_2_memory 0xBBE00000 0x80000>, 
			      <0xBBE80000 &ps_wizard_0_ps11_0_ocm_ram_3_memory 0xBBE80000 0x80000>, 
			      <0xa0000000 &ps_wizard_0_mmi_0_mmi_pcie_region_0 0xa0000000 0x10000000>, 
			      <0xea460000 &ps_wizard_0_ps11_0_lpd_systmr_read 0xea460000 0x10000>, 
			      <0xea470000 &ps_wizard_0_ps11_0_lpd_systmr_ctrl 0xea470000 0x10000>, 
			      <0xeaa00000 &ps_wizard_0_ps11_0_ocm_ctrl_3 0xeaa00000 0x10000>, 
			      <0xeb400000 &ps_wizard_0_ps11_0_ocm_xmpu_0 0xeb400000 0x10000>, 
			      <0xeb410000 &ps_wizard_0_ps11_0_lpd_slcr_0 0xeb410000 0x100000>, 
			      <0xeb510000 &ps_wizard_0_ps11_0_lpd_slcr_secure_0 0xeb510000 0x40000>, 
			      <0xeb580000 &ps_wizard_0_ps11_0_rpu_a 0xeb580000 0x8000>, 
			      <0xeb590000 &ps_wizard_0_ps11_0_rpu_b 0xeb590000 0x8000>, 
			      <0xeb5d0000 &ps_wizard_0_ps11_0_ocm_ctrl_0 0xeb5d0000 0x10000>, 
			      <0xeb5e0000 &ps_wizard_0_ps11_0_crl_0 0xeb5e0000 0x300000>, 
			      <0xeb960000 &ps_wizard_0_ps11_0_ocm_ctrl_1 0xeb960000 0x10000>, 
			      <0xeb980000 &ps_wizard_0_ps11_0_ocm_xmpu_1 0xeb980000 0x10000>, 
			      <0xeb990000 &ps_wizard_0_ps11_0_lpd_xppu_0 0xeb990000 0x10000>, 
			      <0xeb9b0000 &ps_wizard_0_ps11_0_lpd_afi_0 0xeb9b0000 0x10000>, 
			      <0xeb9d0000 &ps_wizard_0_ps11_0_ocm_ctrl_2 0xeb9d0000 0x10000>, 
			      <0xebd00000 &adma0 0xebd00000 0x10000>, 
			      <0xebd10000 &adma1 0xebd10000 0x10000>, 
			      <0xebd20000 &adma2 0xebd20000 0x10000>, 
			      <0xebd30000 &adma3 0xebd30000 0x10000>, 
			      <0xebd40000 &adma4 0xebd40000 0x10000>, 
			      <0xebd50000 &adma5 0xebd50000 0x10000>, 
			      <0xebd60000 &adma6 0xebd60000 0x10000>, 
			      <0xebd70000 &adma7 0xebd70000 0x10000>, 
			      <0xebe8c000 &asu_dma0 0xebe8c000 0x1000>, 
			      <0xec200000 &ps_wizard_0_ps11_0_crf_0 0xec200000 0x100000>, 
			      <0xec810000 &ps_wizard_0_ps11_0_fpd_slv_asild_xmpu_0 0xec810000 0x10000>, 
			      <0xec820000 &ps_wizard_0_ps11_0_fpd_slv_asilb_xmpu_0 0xec820000 0x10000>, 
			      <0xec880000 &ps_wizard_0_ps11_0_fpd_afi_0 0xec880000 0x10000>, 
			      <0xec890000 &ps_wizard_0_ps11_0_fpd_afi_1 0xec890000 0x10000>, 
			      <0xec8a0000 &ps_wizard_0_ps11_0_fpd_afi_2 0xec8a0000 0x10000>, 
			      <0xec8b0000 &ps_wizard_0_ps11_0_fpd_afi_3 0xec8b0000 0x10000>, 
			      <0xec8c0000 &ps_wizard_0_ps11_0_fpd_slcr_0 0xec8c0000 0x10000>, 
			      <0xec8e0000 &ps_wizard_0_ps11_0_fpd_slcr_secure_0 0xec8e0000 0x10000>, 
			      <0xec910000 &ps_wizard_0_ps11_0_fpd_systmr_read 0xec910000 0x10000>, 
			      <0xec920000 &ps_wizard_0_ps11_0_fpd_systmr_ctrl 0xec920000 0x10000>, 
			      <0xecc00000 &ps_wizard_0_ps11_0_apu_0 0xecc00000 0x10000>, 
			      <0xecd00000 &ps_wizard_0_ps11_0_apu_1 0xecd00000 0x10000>, 
			      <0xece00000 &ps_wizard_0_ps11_0_apu_2 0xece00000 0x10000>, 
			      <0xecf00000 &ps_wizard_0_ps11_0_apu_3 0xecf00000 0x10000>, 
			      <0xed000000 &gpu 0xed000000 0x800000>, 
			      <0xed800000 &ps_wizard_0_mmi_0_mmi_pcie0 0xed800000 0x80000>, 
			      <0xed900000 &ps_wizard_0_mmi_0_mmi_gtyp_cfg 0xed900000 0x20000>, 
			      <0xed920000 &mmi_10gbe 0xed920000 0x10000>, 
			      <0xed930000 &ps_wizard_0_mmi_0_mmi_pipe_gem_slcr 0xed930000 0x1000>, 
			      <0xed931000 &mdb_pcie0 0xed931000 0x8000>, 
			      <0xeda00000 &ps_wizard_0_mmi_0_mmi_common 0xeda00000 0x300000>, 
			      <0xedd00000 &mmi_dc 0xedd00000 0x10000>, 
			      <0xedd10000 &ps_wizard_0_mmi_0_mmi_dpdma 0xedd10000 0x10000>, 
			      <0xede00000 &mmi_dptx 0xede00000 0x40000>, 
			      <0xede40000 &ps_wizard_0_mmi_0_mmi_usb3phy_crpara 0xede40000 0x40000>, 
			      <0xede80000 &ps_wizard_0_mmi_0_mmi_trng 0xede80000 0x10000>, 
			      <0xede90000 &ps_wizard_0_mmi_0_mmi_udh_pll 0xede90000 0x10000>, 
			      <0xedea0000 &ps_wizard_0_mmi_0_mmi_udh_slcr 0xedea0000 0x10000>, 
			      <0xedeb0000 &ps_wizard_0_mmi_0_mmi_hdcp 0xedeb0000 0x8000>, 
			      <0xedeb8000 &ps_wizard_0_mmi_0_mmi_usb3phy_tca 0xedeb8000 0x4000>, 
			      <0xedebc000 &ps_wizard_0_mmi_0_mmi_usb2phy 0xedebc000 0x4000>, 
			      <0xedec0000 &mmi_dwc3 0xedec0000 0x130000>, 
			      <0xf0310000 &pmc_ppu1_mdm_0 0xf0310000 0x8000>, 
			      <0xf0800000 &coresight 0xf0800000 0x4000>, 
			      <0xf08f0000 &ps_wizard_0_ps11_0_coresight_lpd_atm 0xf08f0000 0xf000>, 
			      <0xf0c40000 &ps_wizard_0_ps11_0_coresight_fpd_stm 0xf0c40000 0x4000>, 
			      <0xf1010000 &ospi 0xf1010000 0x10000>, 
			      <0xf1020000 &gpio1 0xf1020000 0x10000>, 
			      <0xf10a0000 &ps_wizard_0_ps11_0_pmc_ufs_0 0xf10a0000 0x10000>, 
			      <0xf10b0000 &ufshc 0xf10b0000 0x10000>, 
			      <0xf1110000 &ps_wizard_0_ps11_0_pmc_global_0 0xf1110000 0x50000>, 
			      <0xf11c0000 &dma0 0xf11c0000 0x10000>, 
			      <0xf11d0000 &dma1 0xf11d0000 0x10000>, 
			      <0xf11e0000 &ps_wizard_0_ps11_0_pmc_aes 0xf11e0000 0x10000>, 
			      <0xf11f0000 &ps_wizard_0_ps11_0_pmc_bbram_ctrl 0xf11f0000 0x10000>, 
			      <0xf1200000 &ps_wizard_0_ps11_0_pmc_rsa 0xf1200000 0x10000>, 
			      <0xf1210000 &ps_wizard_0_ps11_0_pmc_sha3 0xf1210000 0x10000>, 
			      <0xf1220000 &ps_wizard_0_ps11_0_pmc_slave_boot 0xf1220000 0x10000>, 
			      <0xf1220000 &ps_wizard_0_mmi_0_pmc_slave_boot 0xf1220000 0x10000>, 
			      <0xf1230000 &pmc_trng 0xf1230000 0x10000>, 
			      <0xf1240000 &ps_wizard_0_ps11_0_pmc_efuse_ctrl 0xf1240000 0x10000>, 
			      <0xf1250000 &ps_wizard_0_ps11_0_pmc_efuse_cache 0xf1250000 0x10000>, 
			      <0xf1260000 &ps_wizard_0_ps11_0_crp_0 0xf1260000 0x10000>, 
			      <0xf1270000 &sysmon0 0xf1270000 0x30000>, 
			      <0xf12a0000 &rtc 0xf12a0000 0x10000>, 
			      <0xf12b0000 &pmc_cfu_apb_0 0xf12b0000 0x10000>, 
			      <0xf12d0000 &pmc_cfi_cframe_0 0xf12d0000 0x1000>, 
			      <0xf12f0000 &ps_wizard_0_ps11_0_pmc_xmpu_0 0xf12f0000 0x10000>, 
			      <0xf1300000 &ps_wizard_0_ps11_0_pmc_xppu_npi_0 0xf1300000 0x10000>, 
			      <0xf1310000 &ps_wizard_0_ps11_0_pmc_xppu_0 0xf1310000 0x10000>, 
			      <0xf1800000 &ps_wizard_0_ps11_0_pmc_sha2 0xf1800000 0x10000>, 
			      <0xf1920000 &serial0 0xf1920000 0x10000>, 
			      <0xf1930000 &serial1 0xf1930000 0x10000>, 
			      <0xf1940000 &i2c0 0xf1940000 0x10000>, 
			      <0xf1950000 &i2c1 0xf1950000 0x10000>, 
			      <0xf19e0000 &can0 0xf19e0000 0x10000>, 
			      <0xf19f0000 &can1 0xf19f0000 0x10000>, 
			      <0xf1a00000 &can2 0xf1a00000 0x10000>, 
			      <0xf1a10000 &can3 0xf1a10000 0x10000>, 
			      <0xf1a20000 &ps_wizard_0_ps11_0_lpd_iou_slcr_0 0xf1a20000 0x20000>, 
			      <0xf1a40000 &ps_wizard_0_ps11_0_lpd_iou_secure_slcr_0 0xf1a40000 0x10000>, 
			      <0xf1a50000 &gpio0 0xf1a50000 0x10000>, 
			      <0xf1a60000 &gem0 0xf1a60000 0x10000>, 
			      <0xf1c00000 &dwc3_1 0xf1c00000 0x100000>, 
			      <0xf1e60000 &ttc0 0xf1e60000 0x10000>, 
			      <0xf1e70000 &ttc1 0xf1e70000 0x10000>, 
			      <0xf1e80000 &ttc2 0xf1e80000 0x10000>, 
			      <0xf1e90000 &ttc3 0xf1e90000 0x10000>, 
			      <0xf1ea0000 &ttc4 0xf1ea0000 0x10000>, 
			      <0xf1eb0000 &ttc5 0xf1eb0000 0x10000>, 
			      <0xf1ec0000 &ttc6 0xf1ec0000 0x10000>, 
			      <0xf1ed0000 &ttc7 0xf1ed0000 0x10000>, 
			      <0xf1ef0000 &usb1 0xf1ef0000 0x10000>, 
			      <0xf2100000 &ps_wizard_0_ps11_0_pmc_slave_boot_stream 0xf2100000 0x10000>, 
			      <0xf2100000 &ps_wizard_0_mmi_0_pmc_slave_boot_stream 0xf2100000 0x10000>, 
			      <0xf6000000 &ps_wizard_0_ps11_0_pmc_ram_npi 0xf6000000 0x2000000>, 
			      <0xf8000000 &ps_wizard_0_ps11_0_fpd_cmn 0xf8000000 0x4000000>, 
			      <0xe2000000 &gic_r52 0xe2000000 0x10000>;
		#ranges-address-cells = <0x1>;
		#ranges-size-cells = <0x1>;
	};
	cpus_r52_6: cpus-r52@6 {
		compatible = "cpus,cluster";
		address-map = <0xf0000000 &amba 0xf0000000 0x10000000>, 
			      <0xf9000000 &amba_rpu 0xf9000000 0x3000>, 
			      <0x100000 &NoC_C0_C1_ddr_memory 0x100000 0x7ff00000>, 
			      <0xedd10000 &mmi_dcdma 0xedd10000 0x1000>, 
			      <0xeb3b2000 &ipi_nobuf3 0xeb3b2000 0x1000>, 
			      <0xBBF00000 &ps_wizard_0_ps11_0_ocm_ram_0_memory 0xBBF00000 0x80000>, 
			      <0xBBF80000 &ps_wizard_0_ps11_0_ocm_ram_1_memory 0xBBF80000 0x80000>, 
			      <0xBBE00000 &ps_wizard_0_ps11_0_ocm_ram_2_memory 0xBBE00000 0x80000>, 
			      <0xBBE80000 &ps_wizard_0_ps11_0_ocm_ram_3_memory 0xBBE80000 0x80000>, 
			      <0xa0000000 &ps_wizard_0_mmi_0_mmi_pcie_region_0 0xa0000000 0x10000000>, 
			      <0xea460000 &ps_wizard_0_ps11_0_lpd_systmr_read 0xea460000 0x10000>, 
			      <0xea470000 &ps_wizard_0_ps11_0_lpd_systmr_ctrl 0xea470000 0x10000>, 
			      <0xeaa00000 &ps_wizard_0_ps11_0_ocm_ctrl_3 0xeaa00000 0x10000>, 
			      <0xeb400000 &ps_wizard_0_ps11_0_ocm_xmpu_0 0xeb400000 0x10000>, 
			      <0xeb410000 &ps_wizard_0_ps11_0_lpd_slcr_0 0xeb410000 0x100000>, 
			      <0xeb510000 &ps_wizard_0_ps11_0_lpd_slcr_secure_0 0xeb510000 0x40000>, 
			      <0xeb580000 &ps_wizard_0_ps11_0_rpu_a 0xeb580000 0x8000>, 
			      <0xeb590000 &ps_wizard_0_ps11_0_rpu_b 0xeb590000 0x8000>, 
			      <0xeb5d0000 &ps_wizard_0_ps11_0_ocm_ctrl_0 0xeb5d0000 0x10000>, 
			      <0xeb5e0000 &ps_wizard_0_ps11_0_crl_0 0xeb5e0000 0x300000>, 
			      <0xeb960000 &ps_wizard_0_ps11_0_ocm_ctrl_1 0xeb960000 0x10000>, 
			      <0xeb980000 &ps_wizard_0_ps11_0_ocm_xmpu_1 0xeb980000 0x10000>, 
			      <0xeb990000 &ps_wizard_0_ps11_0_lpd_xppu_0 0xeb990000 0x10000>, 
			      <0xeb9b0000 &ps_wizard_0_ps11_0_lpd_afi_0 0xeb9b0000 0x10000>, 
			      <0xeb9d0000 &ps_wizard_0_ps11_0_ocm_ctrl_2 0xeb9d0000 0x10000>, 
			      <0xebd00000 &adma0 0xebd00000 0x10000>, 
			      <0xebd10000 &adma1 0xebd10000 0x10000>, 
			      <0xebd20000 &adma2 0xebd20000 0x10000>, 
			      <0xebd30000 &adma3 0xebd30000 0x10000>, 
			      <0xebd40000 &adma4 0xebd40000 0x10000>, 
			      <0xebd50000 &adma5 0xebd50000 0x10000>, 
			      <0xebd60000 &adma6 0xebd60000 0x10000>, 
			      <0xebd70000 &adma7 0xebd70000 0x10000>, 
			      <0xebe8c000 &asu_dma0 0xebe8c000 0x1000>, 
			      <0xec200000 &ps_wizard_0_ps11_0_crf_0 0xec200000 0x100000>, 
			      <0xec810000 &ps_wizard_0_ps11_0_fpd_slv_asild_xmpu_0 0xec810000 0x10000>, 
			      <0xec820000 &ps_wizard_0_ps11_0_fpd_slv_asilb_xmpu_0 0xec820000 0x10000>, 
			      <0xec880000 &ps_wizard_0_ps11_0_fpd_afi_0 0xec880000 0x10000>, 
			      <0xec890000 &ps_wizard_0_ps11_0_fpd_afi_1 0xec890000 0x10000>, 
			      <0xec8a0000 &ps_wizard_0_ps11_0_fpd_afi_2 0xec8a0000 0x10000>, 
			      <0xec8b0000 &ps_wizard_0_ps11_0_fpd_afi_3 0xec8b0000 0x10000>, 
			      <0xec8c0000 &ps_wizard_0_ps11_0_fpd_slcr_0 0xec8c0000 0x10000>, 
			      <0xec8e0000 &ps_wizard_0_ps11_0_fpd_slcr_secure_0 0xec8e0000 0x10000>, 
			      <0xec910000 &ps_wizard_0_ps11_0_fpd_systmr_read 0xec910000 0x10000>, 
			      <0xec920000 &ps_wizard_0_ps11_0_fpd_systmr_ctrl 0xec920000 0x10000>, 
			      <0xecc00000 &ps_wizard_0_ps11_0_apu_0 0xecc00000 0x10000>, 
			      <0xecd00000 &ps_wizard_0_ps11_0_apu_1 0xecd00000 0x10000>, 
			      <0xece00000 &ps_wizard_0_ps11_0_apu_2 0xece00000 0x10000>, 
			      <0xecf00000 &ps_wizard_0_ps11_0_apu_3 0xecf00000 0x10000>, 
			      <0xed000000 &gpu 0xed000000 0x800000>, 
			      <0xed800000 &ps_wizard_0_mmi_0_mmi_pcie0 0xed800000 0x80000>, 
			      <0xed900000 &ps_wizard_0_mmi_0_mmi_gtyp_cfg 0xed900000 0x20000>, 
			      <0xed920000 &mmi_10gbe 0xed920000 0x10000>, 
			      <0xed930000 &ps_wizard_0_mmi_0_mmi_pipe_gem_slcr 0xed930000 0x1000>, 
			      <0xed931000 &mdb_pcie0 0xed931000 0x8000>, 
			      <0xeda00000 &ps_wizard_0_mmi_0_mmi_common 0xeda00000 0x300000>, 
			      <0xedd00000 &mmi_dc 0xedd00000 0x10000>, 
			      <0xedd10000 &ps_wizard_0_mmi_0_mmi_dpdma 0xedd10000 0x10000>, 
			      <0xede00000 &mmi_dptx 0xede00000 0x40000>, 
			      <0xede40000 &ps_wizard_0_mmi_0_mmi_usb3phy_crpara 0xede40000 0x40000>, 
			      <0xede80000 &ps_wizard_0_mmi_0_mmi_trng 0xede80000 0x10000>, 
			      <0xede90000 &ps_wizard_0_mmi_0_mmi_udh_pll 0xede90000 0x10000>, 
			      <0xedea0000 &ps_wizard_0_mmi_0_mmi_udh_slcr 0xedea0000 0x10000>, 
			      <0xedeb0000 &ps_wizard_0_mmi_0_mmi_hdcp 0xedeb0000 0x8000>, 
			      <0xedeb8000 &ps_wizard_0_mmi_0_mmi_usb3phy_tca 0xedeb8000 0x4000>, 
			      <0xedebc000 &ps_wizard_0_mmi_0_mmi_usb2phy 0xedebc000 0x4000>, 
			      <0xedec0000 &mmi_dwc3 0xedec0000 0x130000>, 
			      <0xf0310000 &pmc_ppu1_mdm_0 0xf0310000 0x8000>, 
			      <0xf0800000 &coresight 0xf0800000 0x4000>, 
			      <0xf08f0000 &ps_wizard_0_ps11_0_coresight_lpd_atm 0xf08f0000 0xf000>, 
			      <0xf0c40000 &ps_wizard_0_ps11_0_coresight_fpd_stm 0xf0c40000 0x4000>, 
			      <0xf1010000 &ospi 0xf1010000 0x10000>, 
			      <0xf1020000 &gpio1 0xf1020000 0x10000>, 
			      <0xf10a0000 &ps_wizard_0_ps11_0_pmc_ufs_0 0xf10a0000 0x10000>, 
			      <0xf10b0000 &ufshc 0xf10b0000 0x10000>, 
			      <0xf1110000 &ps_wizard_0_ps11_0_pmc_global_0 0xf1110000 0x50000>, 
			      <0xf11c0000 &dma0 0xf11c0000 0x10000>, 
			      <0xf11d0000 &dma1 0xf11d0000 0x10000>, 
			      <0xf11e0000 &ps_wizard_0_ps11_0_pmc_aes 0xf11e0000 0x10000>, 
			      <0xf11f0000 &ps_wizard_0_ps11_0_pmc_bbram_ctrl 0xf11f0000 0x10000>, 
			      <0xf1200000 &ps_wizard_0_ps11_0_pmc_rsa 0xf1200000 0x10000>, 
			      <0xf1210000 &ps_wizard_0_ps11_0_pmc_sha3 0xf1210000 0x10000>, 
			      <0xf1220000 &ps_wizard_0_ps11_0_pmc_slave_boot 0xf1220000 0x10000>, 
			      <0xf1220000 &ps_wizard_0_mmi_0_pmc_slave_boot 0xf1220000 0x10000>, 
			      <0xf1230000 &pmc_trng 0xf1230000 0x10000>, 
			      <0xf1240000 &ps_wizard_0_ps11_0_pmc_efuse_ctrl 0xf1240000 0x10000>, 
			      <0xf1250000 &ps_wizard_0_ps11_0_pmc_efuse_cache 0xf1250000 0x10000>, 
			      <0xf1260000 &ps_wizard_0_ps11_0_crp_0 0xf1260000 0x10000>, 
			      <0xf1270000 &sysmon0 0xf1270000 0x30000>, 
			      <0xf12a0000 &rtc 0xf12a0000 0x10000>, 
			      <0xf12b0000 &pmc_cfu_apb_0 0xf12b0000 0x10000>, 
			      <0xf12d0000 &pmc_cfi_cframe_0 0xf12d0000 0x1000>, 
			      <0xf12f0000 &ps_wizard_0_ps11_0_pmc_xmpu_0 0xf12f0000 0x10000>, 
			      <0xf1300000 &ps_wizard_0_ps11_0_pmc_xppu_npi_0 0xf1300000 0x10000>, 
			      <0xf1310000 &ps_wizard_0_ps11_0_pmc_xppu_0 0xf1310000 0x10000>, 
			      <0xf1800000 &ps_wizard_0_ps11_0_pmc_sha2 0xf1800000 0x10000>, 
			      <0xf1920000 &serial0 0xf1920000 0x10000>, 
			      <0xf1930000 &serial1 0xf1930000 0x10000>, 
			      <0xf1940000 &i2c0 0xf1940000 0x10000>, 
			      <0xf1950000 &i2c1 0xf1950000 0x10000>, 
			      <0xf19e0000 &can0 0xf19e0000 0x10000>, 
			      <0xf19f0000 &can1 0xf19f0000 0x10000>, 
			      <0xf1a00000 &can2 0xf1a00000 0x10000>, 
			      <0xf1a10000 &can3 0xf1a10000 0x10000>, 
			      <0xf1a20000 &ps_wizard_0_ps11_0_lpd_iou_slcr_0 0xf1a20000 0x20000>, 
			      <0xf1a40000 &ps_wizard_0_ps11_0_lpd_iou_secure_slcr_0 0xf1a40000 0x10000>, 
			      <0xf1a50000 &gpio0 0xf1a50000 0x10000>, 
			      <0xf1a60000 &gem0 0xf1a60000 0x10000>, 
			      <0xf1c00000 &dwc3_1 0xf1c00000 0x100000>, 
			      <0xf1e60000 &ttc0 0xf1e60000 0x10000>, 
			      <0xf1e70000 &ttc1 0xf1e70000 0x10000>, 
			      <0xf1e80000 &ttc2 0xf1e80000 0x10000>, 
			      <0xf1e90000 &ttc3 0xf1e90000 0x10000>, 
			      <0xf1ea0000 &ttc4 0xf1ea0000 0x10000>, 
			      <0xf1eb0000 &ttc5 0xf1eb0000 0x10000>, 
			      <0xf1ec0000 &ttc6 0xf1ec0000 0x10000>, 
			      <0xf1ed0000 &ttc7 0xf1ed0000 0x10000>, 
			      <0xf1ef0000 &usb1 0xf1ef0000 0x10000>, 
			      <0xf2100000 &ps_wizard_0_ps11_0_pmc_slave_boot_stream 0xf2100000 0x10000>, 
			      <0xf2100000 &ps_wizard_0_mmi_0_pmc_slave_boot_stream 0xf2100000 0x10000>, 
			      <0xf6000000 &ps_wizard_0_ps11_0_pmc_ram_npi 0xf6000000 0x2000000>, 
			      <0xf8000000 &ps_wizard_0_ps11_0_fpd_cmn 0xf8000000 0x4000000>, 
			      <0xe2000000 &gic_r52 0xe2000000 0x10000>;
		#ranges-address-cells = <0x1>;
		#ranges-size-cells = <0x1>;
	};
	cpus_r52_7: cpus-r52@7 {
		compatible = "cpus,cluster";
		address-map = <0xf0000000 &amba 0xf0000000 0x10000000>, 
			      <0xf9000000 &amba_rpu 0xf9000000 0x3000>, 
			      <0x100000 &NoC_C0_C1_ddr_memory 0x100000 0x7ff00000>, 
			      <0xedd10000 &mmi_dcdma 0xedd10000 0x1000>, 
			      <0xeb3b3000 &ipi_nobuf4 0xeb3b3000 0x1000>, 
			      <0xBBF00000 &ps_wizard_0_ps11_0_ocm_ram_0_memory 0xBBF00000 0x80000>, 
			      <0xBBF80000 &ps_wizard_0_ps11_0_ocm_ram_1_memory 0xBBF80000 0x80000>, 
			      <0xBBE00000 &ps_wizard_0_ps11_0_ocm_ram_2_memory 0xBBE00000 0x80000>, 
			      <0xBBE80000 &ps_wizard_0_ps11_0_ocm_ram_3_memory 0xBBE80000 0x80000>, 
			      <0xa0000000 &ps_wizard_0_mmi_0_mmi_pcie_region_0 0xa0000000 0x10000000>, 
			      <0xea460000 &ps_wizard_0_ps11_0_lpd_systmr_read 0xea460000 0x10000>, 
			      <0xea470000 &ps_wizard_0_ps11_0_lpd_systmr_ctrl 0xea470000 0x10000>, 
			      <0xeaa00000 &ps_wizard_0_ps11_0_ocm_ctrl_3 0xeaa00000 0x10000>, 
			      <0xeb400000 &ps_wizard_0_ps11_0_ocm_xmpu_0 0xeb400000 0x10000>, 
			      <0xeb410000 &ps_wizard_0_ps11_0_lpd_slcr_0 0xeb410000 0x100000>, 
			      <0xeb510000 &ps_wizard_0_ps11_0_lpd_slcr_secure_0 0xeb510000 0x40000>, 
			      <0xeb580000 &ps_wizard_0_ps11_0_rpu_a 0xeb580000 0x8000>, 
			      <0xeb590000 &ps_wizard_0_ps11_0_rpu_b 0xeb590000 0x8000>, 
			      <0xeb5d0000 &ps_wizard_0_ps11_0_ocm_ctrl_0 0xeb5d0000 0x10000>, 
			      <0xeb5e0000 &ps_wizard_0_ps11_0_crl_0 0xeb5e0000 0x300000>, 
			      <0xeb960000 &ps_wizard_0_ps11_0_ocm_ctrl_1 0xeb960000 0x10000>, 
			      <0xeb980000 &ps_wizard_0_ps11_0_ocm_xmpu_1 0xeb980000 0x10000>, 
			      <0xeb990000 &ps_wizard_0_ps11_0_lpd_xppu_0 0xeb990000 0x10000>, 
			      <0xeb9b0000 &ps_wizard_0_ps11_0_lpd_afi_0 0xeb9b0000 0x10000>, 
			      <0xeb9d0000 &ps_wizard_0_ps11_0_ocm_ctrl_2 0xeb9d0000 0x10000>, 
			      <0xebd00000 &adma0 0xebd00000 0x10000>, 
			      <0xebd10000 &adma1 0xebd10000 0x10000>, 
			      <0xebd20000 &adma2 0xebd20000 0x10000>, 
			      <0xebd30000 &adma3 0xebd30000 0x10000>, 
			      <0xebd40000 &adma4 0xebd40000 0x10000>, 
			      <0xebd50000 &adma5 0xebd50000 0x10000>, 
			      <0xebd60000 &adma6 0xebd60000 0x10000>, 
			      <0xebd70000 &adma7 0xebd70000 0x10000>, 
			      <0xebe8c000 &asu_dma0 0xebe8c000 0x1000>, 
			      <0xec200000 &ps_wizard_0_ps11_0_crf_0 0xec200000 0x100000>, 
			      <0xec810000 &ps_wizard_0_ps11_0_fpd_slv_asild_xmpu_0 0xec810000 0x10000>, 
			      <0xec820000 &ps_wizard_0_ps11_0_fpd_slv_asilb_xmpu_0 0xec820000 0x10000>, 
			      <0xec880000 &ps_wizard_0_ps11_0_fpd_afi_0 0xec880000 0x10000>, 
			      <0xec890000 &ps_wizard_0_ps11_0_fpd_afi_1 0xec890000 0x10000>, 
			      <0xec8a0000 &ps_wizard_0_ps11_0_fpd_afi_2 0xec8a0000 0x10000>, 
			      <0xec8b0000 &ps_wizard_0_ps11_0_fpd_afi_3 0xec8b0000 0x10000>, 
			      <0xec8c0000 &ps_wizard_0_ps11_0_fpd_slcr_0 0xec8c0000 0x10000>, 
			      <0xec8e0000 &ps_wizard_0_ps11_0_fpd_slcr_secure_0 0xec8e0000 0x10000>, 
			      <0xec910000 &ps_wizard_0_ps11_0_fpd_systmr_read 0xec910000 0x10000>, 
			      <0xec920000 &ps_wizard_0_ps11_0_fpd_systmr_ctrl 0xec920000 0x10000>, 
			      <0xecc00000 &ps_wizard_0_ps11_0_apu_0 0xecc00000 0x10000>, 
			      <0xecd00000 &ps_wizard_0_ps11_0_apu_1 0xecd00000 0x10000>, 
			      <0xece00000 &ps_wizard_0_ps11_0_apu_2 0xece00000 0x10000>, 
			      <0xecf00000 &ps_wizard_0_ps11_0_apu_3 0xecf00000 0x10000>, 
			      <0xed000000 &gpu 0xed000000 0x800000>, 
			      <0xed800000 &ps_wizard_0_mmi_0_mmi_pcie0 0xed800000 0x80000>, 
			      <0xed900000 &ps_wizard_0_mmi_0_mmi_gtyp_cfg 0xed900000 0x20000>, 
			      <0xed920000 &mmi_10gbe 0xed920000 0x10000>, 
			      <0xed930000 &ps_wizard_0_mmi_0_mmi_pipe_gem_slcr 0xed930000 0x1000>, 
			      <0xed931000 &mdb_pcie0 0xed931000 0x8000>, 
			      <0xeda00000 &ps_wizard_0_mmi_0_mmi_common 0xeda00000 0x300000>, 
			      <0xedd00000 &mmi_dc 0xedd00000 0x10000>, 
			      <0xedd10000 &ps_wizard_0_mmi_0_mmi_dpdma 0xedd10000 0x10000>, 
			      <0xede00000 &mmi_dptx 0xede00000 0x40000>, 
			      <0xede40000 &ps_wizard_0_mmi_0_mmi_usb3phy_crpara 0xede40000 0x40000>, 
			      <0xede80000 &ps_wizard_0_mmi_0_mmi_trng 0xede80000 0x10000>, 
			      <0xede90000 &ps_wizard_0_mmi_0_mmi_udh_pll 0xede90000 0x10000>, 
			      <0xedea0000 &ps_wizard_0_mmi_0_mmi_udh_slcr 0xedea0000 0x10000>, 
			      <0xedeb0000 &ps_wizard_0_mmi_0_mmi_hdcp 0xedeb0000 0x8000>, 
			      <0xedeb8000 &ps_wizard_0_mmi_0_mmi_usb3phy_tca 0xedeb8000 0x4000>, 
			      <0xedebc000 &ps_wizard_0_mmi_0_mmi_usb2phy 0xedebc000 0x4000>, 
			      <0xedec0000 &mmi_dwc3 0xedec0000 0x130000>, 
			      <0xf0310000 &pmc_ppu1_mdm_0 0xf0310000 0x8000>, 
			      <0xf0800000 &coresight 0xf0800000 0x4000>, 
			      <0xf08f0000 &ps_wizard_0_ps11_0_coresight_lpd_atm 0xf08f0000 0xf000>, 
			      <0xf0c40000 &ps_wizard_0_ps11_0_coresight_fpd_stm 0xf0c40000 0x4000>, 
			      <0xf1010000 &ospi 0xf1010000 0x10000>, 
			      <0xf1020000 &gpio1 0xf1020000 0x10000>, 
			      <0xf10a0000 &ps_wizard_0_ps11_0_pmc_ufs_0 0xf10a0000 0x10000>, 
			      <0xf10b0000 &ufshc 0xf10b0000 0x10000>, 
			      <0xf1110000 &ps_wizard_0_ps11_0_pmc_global_0 0xf1110000 0x50000>, 
			      <0xf11c0000 &dma0 0xf11c0000 0x10000>, 
			      <0xf11d0000 &dma1 0xf11d0000 0x10000>, 
			      <0xf11e0000 &ps_wizard_0_ps11_0_pmc_aes 0xf11e0000 0x10000>, 
			      <0xf11f0000 &ps_wizard_0_ps11_0_pmc_bbram_ctrl 0xf11f0000 0x10000>, 
			      <0xf1200000 &ps_wizard_0_ps11_0_pmc_rsa 0xf1200000 0x10000>, 
			      <0xf1210000 &ps_wizard_0_ps11_0_pmc_sha3 0xf1210000 0x10000>, 
			      <0xf1220000 &ps_wizard_0_ps11_0_pmc_slave_boot 0xf1220000 0x10000>, 
			      <0xf1220000 &ps_wizard_0_mmi_0_pmc_slave_boot 0xf1220000 0x10000>, 
			      <0xf1230000 &pmc_trng 0xf1230000 0x10000>, 
			      <0xf1240000 &ps_wizard_0_ps11_0_pmc_efuse_ctrl 0xf1240000 0x10000>, 
			      <0xf1250000 &ps_wizard_0_ps11_0_pmc_efuse_cache 0xf1250000 0x10000>, 
			      <0xf1260000 &ps_wizard_0_ps11_0_crp_0 0xf1260000 0x10000>, 
			      <0xf1270000 &sysmon0 0xf1270000 0x30000>, 
			      <0xf12a0000 &rtc 0xf12a0000 0x10000>, 
			      <0xf12b0000 &pmc_cfu_apb_0 0xf12b0000 0x10000>, 
			      <0xf12d0000 &pmc_cfi_cframe_0 0xf12d0000 0x1000>, 
			      <0xf12f0000 &ps_wizard_0_ps11_0_pmc_xmpu_0 0xf12f0000 0x10000>, 
			      <0xf1300000 &ps_wizard_0_ps11_0_pmc_xppu_npi_0 0xf1300000 0x10000>, 
			      <0xf1310000 &ps_wizard_0_ps11_0_pmc_xppu_0 0xf1310000 0x10000>, 
			      <0xf1800000 &ps_wizard_0_ps11_0_pmc_sha2 0xf1800000 0x10000>, 
			      <0xf1920000 &serial0 0xf1920000 0x10000>, 
			      <0xf1930000 &serial1 0xf1930000 0x10000>, 
			      <0xf1940000 &i2c0 0xf1940000 0x10000>, 
			      <0xf1950000 &i2c1 0xf1950000 0x10000>, 
			      <0xf19e0000 &can0 0xf19e0000 0x10000>, 
			      <0xf19f0000 &can1 0xf19f0000 0x10000>, 
			      <0xf1a00000 &can2 0xf1a00000 0x10000>, 
			      <0xf1a10000 &can3 0xf1a10000 0x10000>, 
			      <0xf1a20000 &ps_wizard_0_ps11_0_lpd_iou_slcr_0 0xf1a20000 0x20000>, 
			      <0xf1a40000 &ps_wizard_0_ps11_0_lpd_iou_secure_slcr_0 0xf1a40000 0x10000>, 
			      <0xf1a50000 &gpio0 0xf1a50000 0x10000>, 
			      <0xf1a60000 &gem0 0xf1a60000 0x10000>, 
			      <0xf1c00000 &dwc3_1 0xf1c00000 0x100000>, 
			      <0xf1e60000 &ttc0 0xf1e60000 0x10000>, 
			      <0xf1e70000 &ttc1 0xf1e70000 0x10000>, 
			      <0xf1e80000 &ttc2 0xf1e80000 0x10000>, 
			      <0xf1e90000 &ttc3 0xf1e90000 0x10000>, 
			      <0xf1ea0000 &ttc4 0xf1ea0000 0x10000>, 
			      <0xf1eb0000 &ttc5 0xf1eb0000 0x10000>, 
			      <0xf1ec0000 &ttc6 0xf1ec0000 0x10000>, 
			      <0xf1ed0000 &ttc7 0xf1ed0000 0x10000>, 
			      <0xf1ef0000 &usb1 0xf1ef0000 0x10000>, 
			      <0xf2100000 &ps_wizard_0_ps11_0_pmc_slave_boot_stream 0xf2100000 0x10000>, 
			      <0xf2100000 &ps_wizard_0_mmi_0_pmc_slave_boot_stream 0xf2100000 0x10000>, 
			      <0xf6000000 &ps_wizard_0_ps11_0_pmc_ram_npi 0xf6000000 0x2000000>, 
			      <0xf8000000 &ps_wizard_0_ps11_0_fpd_cmn 0xf8000000 0x4000000>, 
			      <0xe2000000 &gic_r52 0xe2000000 0x10000>;
		#ranges-address-cells = <0x1>;
		#ranges-size-cells = <0x1>;
	};
	cpus_r52_8: cpus-r52@8 {
		compatible = "cpus,cluster";
		address-map = <0xf0000000 &amba 0xf0000000 0x10000000>, 
			      <0xf9000000 &amba_rpu 0xf9000000 0x3000>, 
			      <0x100000 &NoC_C0_C1_ddr_memory 0x100000 0x7ff00000>, 
			      <0xedd10000 &mmi_dcdma 0xedd10000 0x1000>, 
			      <0xeb3b4000 &ipi_nobuf5 0xeb3b4000 0x1000>, 
			      <0xBBF00000 &ps_wizard_0_ps11_0_ocm_ram_0_memory 0xBBF00000 0x80000>, 
			      <0xBBF80000 &ps_wizard_0_ps11_0_ocm_ram_1_memory 0xBBF80000 0x80000>, 
			      <0xBBE00000 &ps_wizard_0_ps11_0_ocm_ram_2_memory 0xBBE00000 0x80000>, 
			      <0xBBE80000 &ps_wizard_0_ps11_0_ocm_ram_3_memory 0xBBE80000 0x80000>, 
			      <0xa0000000 &ps_wizard_0_mmi_0_mmi_pcie_region_0 0xa0000000 0x10000000>, 
			      <0xea460000 &ps_wizard_0_ps11_0_lpd_systmr_read 0xea460000 0x10000>, 
			      <0xea470000 &ps_wizard_0_ps11_0_lpd_systmr_ctrl 0xea470000 0x10000>, 
			      <0xeaa00000 &ps_wizard_0_ps11_0_ocm_ctrl_3 0xeaa00000 0x10000>, 
			      <0xeb400000 &ps_wizard_0_ps11_0_ocm_xmpu_0 0xeb400000 0x10000>, 
			      <0xeb410000 &ps_wizard_0_ps11_0_lpd_slcr_0 0xeb410000 0x100000>, 
			      <0xeb510000 &ps_wizard_0_ps11_0_lpd_slcr_secure_0 0xeb510000 0x40000>, 
			      <0xeb580000 &ps_wizard_0_ps11_0_rpu_a 0xeb580000 0x8000>, 
			      <0xeb590000 &ps_wizard_0_ps11_0_rpu_b 0xeb590000 0x8000>, 
			      <0xeb5d0000 &ps_wizard_0_ps11_0_ocm_ctrl_0 0xeb5d0000 0x10000>, 
			      <0xeb5e0000 &ps_wizard_0_ps11_0_crl_0 0xeb5e0000 0x300000>, 
			      <0xeb960000 &ps_wizard_0_ps11_0_ocm_ctrl_1 0xeb960000 0x10000>, 
			      <0xeb980000 &ps_wizard_0_ps11_0_ocm_xmpu_1 0xeb980000 0x10000>, 
			      <0xeb990000 &ps_wizard_0_ps11_0_lpd_xppu_0 0xeb990000 0x10000>, 
			      <0xeb9b0000 &ps_wizard_0_ps11_0_lpd_afi_0 0xeb9b0000 0x10000>, 
			      <0xeb9d0000 &ps_wizard_0_ps11_0_ocm_ctrl_2 0xeb9d0000 0x10000>, 
			      <0xebd00000 &adma0 0xebd00000 0x10000>, 
			      <0xebd10000 &adma1 0xebd10000 0x10000>, 
			      <0xebd20000 &adma2 0xebd20000 0x10000>, 
			      <0xebd30000 &adma3 0xebd30000 0x10000>, 
			      <0xebd40000 &adma4 0xebd40000 0x10000>, 
			      <0xebd50000 &adma5 0xebd50000 0x10000>, 
			      <0xebd60000 &adma6 0xebd60000 0x10000>, 
			      <0xebd70000 &adma7 0xebd70000 0x10000>, 
			      <0xebe8c000 &asu_dma0 0xebe8c000 0x1000>, 
			      <0xec200000 &ps_wizard_0_ps11_0_crf_0 0xec200000 0x100000>, 
			      <0xec810000 &ps_wizard_0_ps11_0_fpd_slv_asild_xmpu_0 0xec810000 0x10000>, 
			      <0xec820000 &ps_wizard_0_ps11_0_fpd_slv_asilb_xmpu_0 0xec820000 0x10000>, 
			      <0xec880000 &ps_wizard_0_ps11_0_fpd_afi_0 0xec880000 0x10000>, 
			      <0xec890000 &ps_wizard_0_ps11_0_fpd_afi_1 0xec890000 0x10000>, 
			      <0xec8a0000 &ps_wizard_0_ps11_0_fpd_afi_2 0xec8a0000 0x10000>, 
			      <0xec8b0000 &ps_wizard_0_ps11_0_fpd_afi_3 0xec8b0000 0x10000>, 
			      <0xec8c0000 &ps_wizard_0_ps11_0_fpd_slcr_0 0xec8c0000 0x10000>, 
			      <0xec8e0000 &ps_wizard_0_ps11_0_fpd_slcr_secure_0 0xec8e0000 0x10000>, 
			      <0xec910000 &ps_wizard_0_ps11_0_fpd_systmr_read 0xec910000 0x10000>, 
			      <0xec920000 &ps_wizard_0_ps11_0_fpd_systmr_ctrl 0xec920000 0x10000>, 
			      <0xecc00000 &ps_wizard_0_ps11_0_apu_0 0xecc00000 0x10000>, 
			      <0xecd00000 &ps_wizard_0_ps11_0_apu_1 0xecd00000 0x10000>, 
			      <0xece00000 &ps_wizard_0_ps11_0_apu_2 0xece00000 0x10000>, 
			      <0xecf00000 &ps_wizard_0_ps11_0_apu_3 0xecf00000 0x10000>, 
			      <0xed000000 &gpu 0xed000000 0x800000>, 
			      <0xed800000 &ps_wizard_0_mmi_0_mmi_pcie0 0xed800000 0x80000>, 
			      <0xed900000 &ps_wizard_0_mmi_0_mmi_gtyp_cfg 0xed900000 0x20000>, 
			      <0xed920000 &mmi_10gbe 0xed920000 0x10000>, 
			      <0xed930000 &ps_wizard_0_mmi_0_mmi_pipe_gem_slcr 0xed930000 0x1000>, 
			      <0xed931000 &mdb_pcie0 0xed931000 0x8000>, 
			      <0xeda00000 &ps_wizard_0_mmi_0_mmi_common 0xeda00000 0x300000>, 
			      <0xedd00000 &mmi_dc 0xedd00000 0x10000>, 
			      <0xedd10000 &ps_wizard_0_mmi_0_mmi_dpdma 0xedd10000 0x10000>, 
			      <0xede00000 &mmi_dptx 0xede00000 0x40000>, 
			      <0xede40000 &ps_wizard_0_mmi_0_mmi_usb3phy_crpara 0xede40000 0x40000>, 
			      <0xede80000 &ps_wizard_0_mmi_0_mmi_trng 0xede80000 0x10000>, 
			      <0xede90000 &ps_wizard_0_mmi_0_mmi_udh_pll 0xede90000 0x10000>, 
			      <0xedea0000 &ps_wizard_0_mmi_0_mmi_udh_slcr 0xedea0000 0x10000>, 
			      <0xedeb0000 &ps_wizard_0_mmi_0_mmi_hdcp 0xedeb0000 0x8000>, 
			      <0xedeb8000 &ps_wizard_0_mmi_0_mmi_usb3phy_tca 0xedeb8000 0x4000>, 
			      <0xedebc000 &ps_wizard_0_mmi_0_mmi_usb2phy 0xedebc000 0x4000>, 
			      <0xedec0000 &mmi_dwc3 0xedec0000 0x130000>, 
			      <0xf0310000 &pmc_ppu1_mdm_0 0xf0310000 0x8000>, 
			      <0xf0800000 &coresight 0xf0800000 0x4000>, 
			      <0xf08f0000 &ps_wizard_0_ps11_0_coresight_lpd_atm 0xf08f0000 0xf000>, 
			      <0xf0c40000 &ps_wizard_0_ps11_0_coresight_fpd_stm 0xf0c40000 0x4000>, 
			      <0xf1010000 &ospi 0xf1010000 0x10000>, 
			      <0xf1020000 &gpio1 0xf1020000 0x10000>, 
			      <0xf10a0000 &ps_wizard_0_ps11_0_pmc_ufs_0 0xf10a0000 0x10000>, 
			      <0xf10b0000 &ufshc 0xf10b0000 0x10000>, 
			      <0xf1110000 &ps_wizard_0_ps11_0_pmc_global_0 0xf1110000 0x50000>, 
			      <0xf11c0000 &dma0 0xf11c0000 0x10000>, 
			      <0xf11d0000 &dma1 0xf11d0000 0x10000>, 
			      <0xf11e0000 &ps_wizard_0_ps11_0_pmc_aes 0xf11e0000 0x10000>, 
			      <0xf11f0000 &ps_wizard_0_ps11_0_pmc_bbram_ctrl 0xf11f0000 0x10000>, 
			      <0xf1200000 &ps_wizard_0_ps11_0_pmc_rsa 0xf1200000 0x10000>, 
			      <0xf1210000 &ps_wizard_0_ps11_0_pmc_sha3 0xf1210000 0x10000>, 
			      <0xf1220000 &ps_wizard_0_ps11_0_pmc_slave_boot 0xf1220000 0x10000>, 
			      <0xf1220000 &ps_wizard_0_mmi_0_pmc_slave_boot 0xf1220000 0x10000>, 
			      <0xf1230000 &pmc_trng 0xf1230000 0x10000>, 
			      <0xf1240000 &ps_wizard_0_ps11_0_pmc_efuse_ctrl 0xf1240000 0x10000>, 
			      <0xf1250000 &ps_wizard_0_ps11_0_pmc_efuse_cache 0xf1250000 0x10000>, 
			      <0xf1260000 &ps_wizard_0_ps11_0_crp_0 0xf1260000 0x10000>, 
			      <0xf1270000 &sysmon0 0xf1270000 0x30000>, 
			      <0xf12a0000 &rtc 0xf12a0000 0x10000>, 
			      <0xf12b0000 &pmc_cfu_apb_0 0xf12b0000 0x10000>, 
			      <0xf12d0000 &pmc_cfi_cframe_0 0xf12d0000 0x1000>, 
			      <0xf12f0000 &ps_wizard_0_ps11_0_pmc_xmpu_0 0xf12f0000 0x10000>, 
			      <0xf1300000 &ps_wizard_0_ps11_0_pmc_xppu_npi_0 0xf1300000 0x10000>, 
			      <0xf1310000 &ps_wizard_0_ps11_0_pmc_xppu_0 0xf1310000 0x10000>, 
			      <0xf1800000 &ps_wizard_0_ps11_0_pmc_sha2 0xf1800000 0x10000>, 
			      <0xf1920000 &serial0 0xf1920000 0x10000>, 
			      <0xf1930000 &serial1 0xf1930000 0x10000>, 
			      <0xf1940000 &i2c0 0xf1940000 0x10000>, 
			      <0xf1950000 &i2c1 0xf1950000 0x10000>, 
			      <0xf19e0000 &can0 0xf19e0000 0x10000>, 
			      <0xf19f0000 &can1 0xf19f0000 0x10000>, 
			      <0xf1a00000 &can2 0xf1a00000 0x10000>, 
			      <0xf1a10000 &can3 0xf1a10000 0x10000>, 
			      <0xf1a20000 &ps_wizard_0_ps11_0_lpd_iou_slcr_0 0xf1a20000 0x20000>, 
			      <0xf1a40000 &ps_wizard_0_ps11_0_lpd_iou_secure_slcr_0 0xf1a40000 0x10000>, 
			      <0xf1a50000 &gpio0 0xf1a50000 0x10000>, 
			      <0xf1a60000 &gem0 0xf1a60000 0x10000>, 
			      <0xf1c00000 &dwc3_1 0xf1c00000 0x100000>, 
			      <0xf1e60000 &ttc0 0xf1e60000 0x10000>, 
			      <0xf1e70000 &ttc1 0xf1e70000 0x10000>, 
			      <0xf1e80000 &ttc2 0xf1e80000 0x10000>, 
			      <0xf1e90000 &ttc3 0xf1e90000 0x10000>, 
			      <0xf1ea0000 &ttc4 0xf1ea0000 0x10000>, 
			      <0xf1eb0000 &ttc5 0xf1eb0000 0x10000>, 
			      <0xf1ec0000 &ttc6 0xf1ec0000 0x10000>, 
			      <0xf1ed0000 &ttc7 0xf1ed0000 0x10000>, 
			      <0xf1ef0000 &usb1 0xf1ef0000 0x10000>, 
			      <0xf2100000 &ps_wizard_0_ps11_0_pmc_slave_boot_stream 0xf2100000 0x10000>, 
			      <0xf2100000 &ps_wizard_0_mmi_0_pmc_slave_boot_stream 0xf2100000 0x10000>, 
			      <0xf6000000 &ps_wizard_0_ps11_0_pmc_ram_npi 0xf6000000 0x2000000>, 
			      <0xf8000000 &ps_wizard_0_ps11_0_fpd_cmn 0xf8000000 0x4000000>, 
			      <0xe2000000 &gic_r52 0xe2000000 0x10000>;
		#ranges-address-cells = <0x1>;
		#ranges-size-cells = <0x1>;
	};
	cpus_r52_9: cpus-r52@9 {
		compatible = "cpus,cluster";
		address-map = <0xf0000000 &amba 0xf0000000 0x10000000>, 
			      <0xf9000000 &amba_rpu 0xf9000000 0x3000>, 
			      <0x100000 &NoC_C0_C1_ddr_memory 0x100000 0x7ff00000>, 
			      <0xedd10000 &mmi_dcdma 0xedd10000 0x1000>, 
			      <0xeb3b5000 &ipi_nobuf6 0xeb3b5000 0x1000>, 
			      <0xBBF00000 &ps_wizard_0_ps11_0_ocm_ram_0_memory 0xBBF00000 0x80000>, 
			      <0xBBF80000 &ps_wizard_0_ps11_0_ocm_ram_1_memory 0xBBF80000 0x80000>, 
			      <0xBBE00000 &ps_wizard_0_ps11_0_ocm_ram_2_memory 0xBBE00000 0x80000>, 
			      <0xBBE80000 &ps_wizard_0_ps11_0_ocm_ram_3_memory 0xBBE80000 0x80000>, 
			      <0xa0000000 &ps_wizard_0_mmi_0_mmi_pcie_region_0 0xa0000000 0x10000000>, 
			      <0xea460000 &ps_wizard_0_ps11_0_lpd_systmr_read 0xea460000 0x10000>, 
			      <0xea470000 &ps_wizard_0_ps11_0_lpd_systmr_ctrl 0xea470000 0x10000>, 
			      <0xeaa00000 &ps_wizard_0_ps11_0_ocm_ctrl_3 0xeaa00000 0x10000>, 
			      <0xeb400000 &ps_wizard_0_ps11_0_ocm_xmpu_0 0xeb400000 0x10000>, 
			      <0xeb410000 &ps_wizard_0_ps11_0_lpd_slcr_0 0xeb410000 0x100000>, 
			      <0xeb510000 &ps_wizard_0_ps11_0_lpd_slcr_secure_0 0xeb510000 0x40000>, 
			      <0xeb580000 &ps_wizard_0_ps11_0_rpu_a 0xeb580000 0x8000>, 
			      <0xeb590000 &ps_wizard_0_ps11_0_rpu_b 0xeb590000 0x8000>, 
			      <0xeb5d0000 &ps_wizard_0_ps11_0_ocm_ctrl_0 0xeb5d0000 0x10000>, 
			      <0xeb5e0000 &ps_wizard_0_ps11_0_crl_0 0xeb5e0000 0x300000>, 
			      <0xeb960000 &ps_wizard_0_ps11_0_ocm_ctrl_1 0xeb960000 0x10000>, 
			      <0xeb980000 &ps_wizard_0_ps11_0_ocm_xmpu_1 0xeb980000 0x10000>, 
			      <0xeb990000 &ps_wizard_0_ps11_0_lpd_xppu_0 0xeb990000 0x10000>, 
			      <0xeb9b0000 &ps_wizard_0_ps11_0_lpd_afi_0 0xeb9b0000 0x10000>, 
			      <0xeb9d0000 &ps_wizard_0_ps11_0_ocm_ctrl_2 0xeb9d0000 0x10000>, 
			      <0xebd00000 &adma0 0xebd00000 0x10000>, 
			      <0xebd10000 &adma1 0xebd10000 0x10000>, 
			      <0xebd20000 &adma2 0xebd20000 0x10000>, 
			      <0xebd30000 &adma3 0xebd30000 0x10000>, 
			      <0xebd40000 &adma4 0xebd40000 0x10000>, 
			      <0xebd50000 &adma5 0xebd50000 0x10000>, 
			      <0xebd60000 &adma6 0xebd60000 0x10000>, 
			      <0xebd70000 &adma7 0xebd70000 0x10000>, 
			      <0xebe8c000 &asu_dma0 0xebe8c000 0x1000>, 
			      <0xec200000 &ps_wizard_0_ps11_0_crf_0 0xec200000 0x100000>, 
			      <0xec810000 &ps_wizard_0_ps11_0_fpd_slv_asild_xmpu_0 0xec810000 0x10000>, 
			      <0xec820000 &ps_wizard_0_ps11_0_fpd_slv_asilb_xmpu_0 0xec820000 0x10000>, 
			      <0xec880000 &ps_wizard_0_ps11_0_fpd_afi_0 0xec880000 0x10000>, 
			      <0xec890000 &ps_wizard_0_ps11_0_fpd_afi_1 0xec890000 0x10000>, 
			      <0xec8a0000 &ps_wizard_0_ps11_0_fpd_afi_2 0xec8a0000 0x10000>, 
			      <0xec8b0000 &ps_wizard_0_ps11_0_fpd_afi_3 0xec8b0000 0x10000>, 
			      <0xec8c0000 &ps_wizard_0_ps11_0_fpd_slcr_0 0xec8c0000 0x10000>, 
			      <0xec8e0000 &ps_wizard_0_ps11_0_fpd_slcr_secure_0 0xec8e0000 0x10000>, 
			      <0xec910000 &ps_wizard_0_ps11_0_fpd_systmr_read 0xec910000 0x10000>, 
			      <0xec920000 &ps_wizard_0_ps11_0_fpd_systmr_ctrl 0xec920000 0x10000>, 
			      <0xecc00000 &ps_wizard_0_ps11_0_apu_0 0xecc00000 0x10000>, 
			      <0xecd00000 &ps_wizard_0_ps11_0_apu_1 0xecd00000 0x10000>, 
			      <0xece00000 &ps_wizard_0_ps11_0_apu_2 0xece00000 0x10000>, 
			      <0xecf00000 &ps_wizard_0_ps11_0_apu_3 0xecf00000 0x10000>, 
			      <0xed000000 &gpu 0xed000000 0x800000>, 
			      <0xed800000 &ps_wizard_0_mmi_0_mmi_pcie0 0xed800000 0x80000>, 
			      <0xed900000 &ps_wizard_0_mmi_0_mmi_gtyp_cfg 0xed900000 0x20000>, 
			      <0xed920000 &mmi_10gbe 0xed920000 0x10000>, 
			      <0xed930000 &ps_wizard_0_mmi_0_mmi_pipe_gem_slcr 0xed930000 0x1000>, 
			      <0xed931000 &mdb_pcie0 0xed931000 0x8000>, 
			      <0xeda00000 &ps_wizard_0_mmi_0_mmi_common 0xeda00000 0x300000>, 
			      <0xedd00000 &mmi_dc 0xedd00000 0x10000>, 
			      <0xedd10000 &ps_wizard_0_mmi_0_mmi_dpdma 0xedd10000 0x10000>, 
			      <0xede00000 &mmi_dptx 0xede00000 0x40000>, 
			      <0xede40000 &ps_wizard_0_mmi_0_mmi_usb3phy_crpara 0xede40000 0x40000>, 
			      <0xede80000 &ps_wizard_0_mmi_0_mmi_trng 0xede80000 0x10000>, 
			      <0xede90000 &ps_wizard_0_mmi_0_mmi_udh_pll 0xede90000 0x10000>, 
			      <0xedea0000 &ps_wizard_0_mmi_0_mmi_udh_slcr 0xedea0000 0x10000>, 
			      <0xedeb0000 &ps_wizard_0_mmi_0_mmi_hdcp 0xedeb0000 0x8000>, 
			      <0xedeb8000 &ps_wizard_0_mmi_0_mmi_usb3phy_tca 0xedeb8000 0x4000>, 
			      <0xedebc000 &ps_wizard_0_mmi_0_mmi_usb2phy 0xedebc000 0x4000>, 
			      <0xedec0000 &mmi_dwc3 0xedec0000 0x130000>, 
			      <0xf0310000 &pmc_ppu1_mdm_0 0xf0310000 0x8000>, 
			      <0xf0800000 &coresight 0xf0800000 0x4000>, 
			      <0xf08f0000 &ps_wizard_0_ps11_0_coresight_lpd_atm 0xf08f0000 0xf000>, 
			      <0xf0c40000 &ps_wizard_0_ps11_0_coresight_fpd_stm 0xf0c40000 0x4000>, 
			      <0xf1010000 &ospi 0xf1010000 0x10000>, 
			      <0xf1020000 &gpio1 0xf1020000 0x10000>, 
			      <0xf10a0000 &ps_wizard_0_ps11_0_pmc_ufs_0 0xf10a0000 0x10000>, 
			      <0xf10b0000 &ufshc 0xf10b0000 0x10000>, 
			      <0xf1110000 &ps_wizard_0_ps11_0_pmc_global_0 0xf1110000 0x50000>, 
			      <0xf11c0000 &dma0 0xf11c0000 0x10000>, 
			      <0xf11d0000 &dma1 0xf11d0000 0x10000>, 
			      <0xf11e0000 &ps_wizard_0_ps11_0_pmc_aes 0xf11e0000 0x10000>, 
			      <0xf11f0000 &ps_wizard_0_ps11_0_pmc_bbram_ctrl 0xf11f0000 0x10000>, 
			      <0xf1200000 &ps_wizard_0_ps11_0_pmc_rsa 0xf1200000 0x10000>, 
			      <0xf1210000 &ps_wizard_0_ps11_0_pmc_sha3 0xf1210000 0x10000>, 
			      <0xf1220000 &ps_wizard_0_ps11_0_pmc_slave_boot 0xf1220000 0x10000>, 
			      <0xf1220000 &ps_wizard_0_mmi_0_pmc_slave_boot 0xf1220000 0x10000>, 
			      <0xf1230000 &pmc_trng 0xf1230000 0x10000>, 
			      <0xf1240000 &ps_wizard_0_ps11_0_pmc_efuse_ctrl 0xf1240000 0x10000>, 
			      <0xf1250000 &ps_wizard_0_ps11_0_pmc_efuse_cache 0xf1250000 0x10000>, 
			      <0xf1260000 &ps_wizard_0_ps11_0_crp_0 0xf1260000 0x10000>, 
			      <0xf1270000 &sysmon0 0xf1270000 0x30000>, 
			      <0xf12a0000 &rtc 0xf12a0000 0x10000>, 
			      <0xf12b0000 &pmc_cfu_apb_0 0xf12b0000 0x10000>, 
			      <0xf12d0000 &pmc_cfi_cframe_0 0xf12d0000 0x1000>, 
			      <0xf12f0000 &ps_wizard_0_ps11_0_pmc_xmpu_0 0xf12f0000 0x10000>, 
			      <0xf1300000 &ps_wizard_0_ps11_0_pmc_xppu_npi_0 0xf1300000 0x10000>, 
			      <0xf1310000 &ps_wizard_0_ps11_0_pmc_xppu_0 0xf1310000 0x10000>, 
			      <0xf1800000 &ps_wizard_0_ps11_0_pmc_sha2 0xf1800000 0x10000>, 
			      <0xf1920000 &serial0 0xf1920000 0x10000>, 
			      <0xf1930000 &serial1 0xf1930000 0x10000>, 
			      <0xf1940000 &i2c0 0xf1940000 0x10000>, 
			      <0xf1950000 &i2c1 0xf1950000 0x10000>, 
			      <0xf19e0000 &can0 0xf19e0000 0x10000>, 
			      <0xf19f0000 &can1 0xf19f0000 0x10000>, 
			      <0xf1a00000 &can2 0xf1a00000 0x10000>, 
			      <0xf1a10000 &can3 0xf1a10000 0x10000>, 
			      <0xf1a20000 &ps_wizard_0_ps11_0_lpd_iou_slcr_0 0xf1a20000 0x20000>, 
			      <0xf1a40000 &ps_wizard_0_ps11_0_lpd_iou_secure_slcr_0 0xf1a40000 0x10000>, 
			      <0xf1a50000 &gpio0 0xf1a50000 0x10000>, 
			      <0xf1a60000 &gem0 0xf1a60000 0x10000>, 
			      <0xf1c00000 &dwc3_1 0xf1c00000 0x100000>, 
			      <0xf1e60000 &ttc0 0xf1e60000 0x10000>, 
			      <0xf1e70000 &ttc1 0xf1e70000 0x10000>, 
			      <0xf1e80000 &ttc2 0xf1e80000 0x10000>, 
			      <0xf1e90000 &ttc3 0xf1e90000 0x10000>, 
			      <0xf1ea0000 &ttc4 0xf1ea0000 0x10000>, 
			      <0xf1eb0000 &ttc5 0xf1eb0000 0x10000>, 
			      <0xf1ec0000 &ttc6 0xf1ec0000 0x10000>, 
			      <0xf1ed0000 &ttc7 0xf1ed0000 0x10000>, 
			      <0xf1ef0000 &usb1 0xf1ef0000 0x10000>, 
			      <0xf2100000 &ps_wizard_0_ps11_0_pmc_slave_boot_stream 0xf2100000 0x10000>, 
			      <0xf2100000 &ps_wizard_0_mmi_0_pmc_slave_boot_stream 0xf2100000 0x10000>, 
			      <0xf6000000 &ps_wizard_0_ps11_0_pmc_ram_npi 0xf6000000 0x2000000>, 
			      <0xf8000000 &ps_wizard_0_ps11_0_fpd_cmn 0xf8000000 0x4000000>, 
			      <0xe2000000 &gic_r52 0xe2000000 0x10000>;
		#ranges-address-cells = <0x1>;
		#ranges-size-cells = <0x1>;
	};
	cpus_microblaze_0: cpus_microblaze@0 {
		compatible = "cpus,cluster";
		address-map = <0xf0000000 &amba 0xf0000000 0x10000000>, 
			      <0xeb320000 &ipi_pmc 0xeb320000 0x10000>, 
			      <0xeb390000 &ipi_pmc_nobuf 0xeb390000 0x10000>, 
			      <0xebd00000 &adma0 0xebd00000 0x10000>, 
			      <0xebd10000 &adma1 0xebd10000 0x10000>, 
			      <0xebd20000 &adma2 0xebd20000 0x10000>, 
			      <0xebd30000 &adma3 0xebd30000 0x10000>, 
			      <0xebd40000 &adma4 0xebd40000 0x10000>, 
			      <0xebd50000 &adma5 0xebd50000 0x10000>, 
			      <0xebd60000 &adma6 0xebd60000 0x10000>, 
			      <0xebd70000 &adma7 0xebd70000 0x10000>, 
			      <0xf0310000 &pmc_ppu1_mdm_0 0xf0310000 0x8000>, 
			      <0xf1010000 &ospi 0xf1010000 0x10000>, 
			      <0xf1020000 &gpio1 0xf1020000 0x10000>, 
			      <0xf10b0000 &ufshc 0xf10b0000 0x10000>, 
			      <0xf11c0000 &dma0 0xf11c0000 0x10000>, 
			      <0xf11d0000 &dma1 0xf11d0000 0x10000>, 
			      <0xf1230000 &pmc_trng 0xf1230000 0x10000>, 
			      <0xf1270000 &sysmon0 0xf1270000 0x30000>, 
			      <0xf12b0000 &pmc_cfu_apb_0 0xf12b0000 0x10000>, 
			      <0xf12d0000 &pmc_cfi_cframe_0 0xf12d0000 0x1000>, 
			      <0xf1920000 &serial0 0xf1920000 0x10000>, 
			      <0xf1930000 &serial1 0xf1930000 0x10000>, 
			      <0xf1940000 &i2c0 0xf1940000 0x10000>, 
			      <0xf1950000 &i2c1 0xf1950000 0x10000>, 
			      <0xf1a50000 &gpio0 0xf1a50000 0x10000>, 
			      <0xf1a60000 &gem0 0xf1a60000 0x10000>, 
			      <0xf1c00000 &dwc3_1 0xf1c00000 0x100000>, 
			      <0xf1e60000 &ttc0 0xf1e60000 0x10000>, 
			      <0xf1e70000 &ttc1 0xf1e70000 0x10000>, 
			      <0xf1e80000 &ttc2 0xf1e80000 0x10000>, 
			      <0xf1e90000 &ttc3 0xf1e90000 0x10000>, 
			      <0xf1ea0000 &ttc4 0xf1ea0000 0x10000>, 
			      <0xf1eb0000 &ttc5 0xf1eb0000 0x10000>, 
			      <0xf1ec0000 &ttc6 0xf1ec0000 0x10000>, 
			      <0xf1ed0000 &ttc7 0xf1ed0000 0x10000>, 
			      <0xf1ef0000 &usb1 0xf1ef0000 0x10000>, 
			      <0xf0300000 &iomodule0 0xf0300000 0x1000>;
		#ranges-address-cells = <0x1>;
		#ranges-size-cells = <0x1>;
	};
	cpus_asu: cpus_asu@0 {
		compatible = "cpus,cluster";
		address-map = <0xf0000000 &amba 0xf0000000 0x10000000>, 
			      <0x00000000 &NoC_C0_C1_ddr_memory 0x00000000 0x80000000>, 
			      <0xedd10000 &mmi_dcdma 0xedd10000 0x1000>, 
			      <0xeb310000 &ipi_asu 0xeb310000 0x10000>, 
			      <0xBBF00000 &ps_wizard_0_ps11_0_ocm_ram_0_memory 0xBBF00000 0x80000>, 
			      <0xBBF80000 &ps_wizard_0_ps11_0_ocm_ram_1_memory 0xBBF80000 0x80000>, 
			      <0xBBE00000 &ps_wizard_0_ps11_0_ocm_ram_2_memory 0xBBE00000 0x80000>, 
			      <0xBBE80000 &ps_wizard_0_ps11_0_ocm_ram_3_memory 0xBBE80000 0x80000>, 
			      <0xa0000000 &ps_wizard_0_mmi_0_mmi_pcie_region_0 0xa0000000 0x10000000>, 
			      <0xea460000 &ps_wizard_0_ps11_0_lpd_systmr_read 0xea460000 0x10000>, 
			      <0xea470000 &ps_wizard_0_ps11_0_lpd_systmr_ctrl 0xea470000 0x10000>, 
			      <0xeaa00000 &ps_wizard_0_ps11_0_ocm_ctrl_3 0xeaa00000 0x10000>, 
			      <0xeb400000 &ps_wizard_0_ps11_0_ocm_xmpu_0 0xeb400000 0x10000>, 
			      <0xeb410000 &ps_wizard_0_ps11_0_lpd_slcr_0 0xeb410000 0x100000>, 
			      <0xeb510000 &ps_wizard_0_ps11_0_lpd_slcr_secure_0 0xeb510000 0x40000>, 
			      <0xeb5d0000 &ps_wizard_0_ps11_0_ocm_ctrl_0 0xeb5d0000 0x10000>, 
			      <0xeb5e0000 &ps_wizard_0_ps11_0_crl_0 0xeb5e0000 0x300000>, 
			      <0xeb960000 &ps_wizard_0_ps11_0_ocm_ctrl_1 0xeb960000 0x10000>, 
			      <0xeb980000 &ps_wizard_0_ps11_0_ocm_xmpu_1 0xeb980000 0x10000>, 
			      <0xeb990000 &ps_wizard_0_ps11_0_lpd_xppu_0 0xeb990000 0x10000>, 
			      <0xeb9b0000 &ps_wizard_0_ps11_0_lpd_afi_0 0xeb9b0000 0x10000>, 
			      <0xeb9d0000 &ps_wizard_0_ps11_0_ocm_ctrl_2 0xeb9d0000 0x10000>, 
			      <0xeba00000 &r52_0a_atcm_global 0xeba00000 0x10000>, 
			      <0xeba10000 &r52_0a_btcm_global 0xeba10000 0x8000>, 
			      <0xeba20000 &r52_0a_ctcm_global 0xeba20000 0x8000>, 
			      <0xeba40000 &r52_1a_atcm_global 0xeba40000 0x10000>, 
			      <0xeba50000 &r52_1a_btcm_global 0xeba50000 0x8000>, 
			      <0xeba60000 &r52_1a_ctcm_global 0xeba60000 0x8000>, 
			      <0xeba80000 &r52_0b_atcm_global 0xeba80000 0x10000>, 
			      <0xeba90000 &r52_0b_btcm_global 0xeba90000 0x8000>, 
			      <0xebaa0000 &r52_0b_ctcm_global 0xebaa0000 0x8000>, 
			      <0xebac0000 &r52_1b_atcm_global 0xebac0000 0x10000>, 
			      <0xebad0000 &r52_1b_btcm_global 0xebad0000 0x8000>, 
			      <0xebae0000 &r52_1b_ctcm_global 0xebae0000 0x8000>, 
			      <0xebb00000 &r52_0c_atcm_global 0xebb00000 0x10000>, 
			      <0xebb10000 &r52_0c_btcm_global 0xebb10000 0x8000>, 
			      <0xebb20000 &r52_0c_ctcm_global 0xebb20000 0x8000>, 
			      <0xebb40000 &r52_1c_atcm_global 0xebb40000 0x10000>, 
			      <0xebb50000 &r52_1c_btcm_global 0xebb50000 0x8000>, 
			      <0xebb60000 &r52_1c_ctcm_global 0xebb60000 0x8000>, 
			      <0xebb80000 &r52_0d_atcm_global 0xebb80000 0x10000>, 
			      <0xebb90000 &r52_0d_btcm_global 0xebb90000 0x8000>, 
			      <0xebba0000 &r52_0d_ctcm_global 0xebba0000 0x8000>, 
			      <0xebbc0000 &r52_1d_atcm_global 0xebbc0000 0x10000>, 
			      <0xebbd0000 &r52_1d_btcm_global 0xebbd0000 0x8000>, 
			      <0xebbe0000 &r52_1d_ctcm_global 0xebbe0000 0x8000>, 
			      <0xebc00000 &r52_0e_atcm_global 0xebc00000 0x10000>, 
			      <0xebc10000 &r52_0e_btcm_global 0xebc10000 0x8000>, 
			      <0xebc20000 &r52_0e_ctcm_global 0xebc20000 0x8000>, 
			      <0xebc40000 &r52_1e_atcm_global 0xebc40000 0x10000>, 
			      <0xebc50000 &r52_1e_btcm_global 0xebc50000 0x8000>, 
			      <0xebc60000 &r52_1e_ctcm_global 0xebc60000 0x8000>, 
			      <0xebe8c000 &asu_dma0 0xebe8c000 0x1000>, 
			      <0xec200000 &ps_wizard_0_ps11_0_crf_0 0xec200000 0x100000>, 
			      <0xec810000 &ps_wizard_0_ps11_0_fpd_slv_asild_xmpu_0 0xec810000 0x10000>, 
			      <0xec820000 &ps_wizard_0_ps11_0_fpd_slv_asilb_xmpu_0 0xec820000 0x10000>, 
			      <0xec8c0000 &ps_wizard_0_ps11_0_fpd_slcr_0 0xec8c0000 0x10000>, 
			      <0xec8e0000 &ps_wizard_0_ps11_0_fpd_slcr_secure_0 0xec8e0000 0x10000>, 
			      <0xec910000 &ps_wizard_0_ps11_0_fpd_systmr_read 0xec910000 0x10000>, 
			      <0xec920000 &ps_wizard_0_ps11_0_fpd_systmr_ctrl 0xec920000 0x10000>, 
			      <0xecc00000 &ps_wizard_0_ps11_0_apu_0 0xecc00000 0x10000>, 
			      <0xecd00000 &ps_wizard_0_ps11_0_apu_1 0xecd00000 0x10000>, 
			      <0xece00000 &ps_wizard_0_ps11_0_apu_2 0xece00000 0x10000>, 
			      <0xecf00000 &ps_wizard_0_ps11_0_apu_3 0xecf00000 0x10000>, 
			      <0xed000000 &gpu 0xed000000 0x800000>, 
			      <0xed800000 &ps_wizard_0_mmi_0_mmi_pcie0 0xed800000 0x80000>, 
			      <0xed900000 &ps_wizard_0_mmi_0_mmi_gtyp_cfg 0xed900000 0x20000>, 
			      <0xed920000 &mmi_10gbe 0xed920000 0x10000>, 
			      <0xed930000 &ps_wizard_0_mmi_0_mmi_pipe_gem_slcr 0xed930000 0x1000>, 
			      <0xed931000 &mdb_pcie0 0xed931000 0x8000>, 
			      <0xeda00000 &ps_wizard_0_mmi_0_mmi_common 0xeda00000 0x300000>, 
			      <0xedd00000 &mmi_dc 0xedd00000 0x10000>, 
			      <0xedd10000 &ps_wizard_0_mmi_0_mmi_dpdma 0xedd10000 0x10000>, 
			      <0xede00000 &mmi_dptx 0xede00000 0x40000>, 
			      <0xede40000 &ps_wizard_0_mmi_0_mmi_usb3phy_crpara 0xede40000 0x40000>, 
			      <0xede80000 &ps_wizard_0_mmi_0_mmi_trng 0xede80000 0x10000>, 
			      <0xede90000 &ps_wizard_0_mmi_0_mmi_udh_pll 0xede90000 0x10000>, 
			      <0xedea0000 &ps_wizard_0_mmi_0_mmi_udh_slcr 0xedea0000 0x10000>, 
			      <0xedeb0000 &ps_wizard_0_mmi_0_mmi_hdcp 0xedeb0000 0x8000>, 
			      <0xedeb8000 &ps_wizard_0_mmi_0_mmi_usb3phy_tca 0xedeb8000 0x4000>, 
			      <0xedebc000 &ps_wizard_0_mmi_0_mmi_usb2phy 0xedebc000 0x4000>, 
			      <0xedec0000 &mmi_dwc3 0xedec0000 0x130000>, 
			      <0xf1020000 &gpio1 0xf1020000 0x10000>, 
			      <0xf1110000 &ps_wizard_0_ps11_0_pmc_global_0 0xf1110000 0x50000>, 
			      <0xf1220000 &ps_wizard_0_ps11_0_pmc_slave_boot 0xf1220000 0x10000>, 
			      <0xf1220000 &ps_wizard_0_mmi_0_pmc_slave_boot 0xf1220000 0x10000>, 
			      <0xf1240000 &ps_wizard_0_ps11_0_pmc_efuse_ctrl 0xf1240000 0x10000>, 
			      <0xf1250000 &ps_wizard_0_ps11_0_pmc_efuse_cache 0xf1250000 0x10000>, 
			      <0xf1260000 &ps_wizard_0_ps11_0_crp_0 0xf1260000 0x10000>, 
			      <0xf12a0000 &rtc 0xf12a0000 0x10000>, 
			      <0xf1920000 &serial0 0xf1920000 0x10000>, 
			      <0xf1930000 &serial1 0xf1930000 0x10000>, 
			      <0xf1940000 &i2c0 0xf1940000 0x10000>, 
			      <0xf1950000 &i2c1 0xf1950000 0x10000>, 
			      <0xf1a20000 &ps_wizard_0_ps11_0_lpd_iou_slcr_0 0xf1a20000 0x20000>, 
			      <0xf1a40000 &ps_wizard_0_ps11_0_lpd_iou_secure_slcr_0 0xf1a40000 0x10000>, 
			      <0xf1a50000 &gpio0 0xf1a50000 0x10000>, 
			      <0xf1c00000 &dwc3_1 0xf1c00000 0x100000>, 
			      <0xf1ef0000 &usb1 0xf1ef0000 0x10000>, 
			      <0xf2100000 &ps_wizard_0_ps11_0_pmc_slave_boot_stream 0xf2100000 0x10000>, 
			      <0xf2100000 &ps_wizard_0_mmi_0_pmc_slave_boot_stream 0xf2100000 0x10000>, 
			      <0xf6000000 &ps_wizard_0_ps11_0_pmc_ram_npi 0xf6000000 0x2000000>, 
			      <0xebe00000 &ps_wizard_0_ps11_0_asu_ram_instr_cntlr 0xebe00000 0x40000>, 
			      <0xebe40000 &ps_wizard_0_ps11_0_asu_ram_data_cntlr 0xebe40000 0x20000>, 
			      <0xebe80000 &asu_iomodule0 0xebe80000 0x8000>, 
			      <0xebe88000 &ps_wizard_0_ps11_0_asu_aes 0xebe88000 0x2000>, 
			      <0xebe8a000 &ps_wizard_0_ps11_0_asu_keys 0xebe8a000 0x2000>, 
			      <0xebe8d000 &asu_dma1 0xebe8d000 0x1000>, 
			      <0xebe8e000 &ps_wizard_0_ps11_0_asu_local 0xebe8e000 0x2000>, 
			      <0xebea0000 &ps_wizard_0_ps11_0_asu_ram_instr_ecc_ctrl 0xebea0000 0x10000>, 
			      <0xebeb0000 &ps_wizard_0_ps11_0_asu_ram_data_ecc_ctrl 0xebeb0000 0x10000>, 
			      <0xebec0000 &ps_wizard_0_ps11_0_asu_tmr_manager 0xebec0000 0x10000>, 
			      <0xebed0000 &ps_wizard_0_ps11_0_asu_tmr_inject 0xebed0000 0x10000>, 
			      <0xebee0000 &ps_wizard_0_ps11_0_asu_tmr_trace 0xebee0000 0x10000>, 
			      <0xebef0000 &ps_wizard_0_ps11_0_asu_mdm_hsd 0xebef0000 0x10000>, 
			      <0xebf00000 &ps_wizard_0_ps11_0_asu_ecc 0xebf00000 0x10000>, 
			      <0xebf20000 &ps_wizard_0_ps11_0_asu_trng 0xebf20000 0x10000>, 
			      <0xebf30000 &ps_wizard_0_ps11_0_asu_sha2 0xebf30000 0x10000>, 
			      <0xebf40000 &ps_wizard_0_ps11_0_asu_sha3 0xebf40000 0x10000>, 
			      <0xebf50000 &ps_wizard_0_ps11_0_asu_rsa 0xebf50000 0x10000>, 
			      <0xebf60000 &ps_wizard_0_ps11_0_asu_xmpu 0xebf60000 0x10000>, 
			      <0xebf70000 &ps_wizard_0_ps11_0_intasu_config 0xebf70000 0xf000>, 
			      <0xebf7f000 &ps_wizard_0_ps11_0_intasu_gpv 0xebf7f000 0x1000>, 
			      <0xebf80000 &ps_wizard_0_ps11_0_asu_global 0xebf80000 0x20000>;
		#ranges-address-cells = <0x1>;
		#ranges-size-cells = <0x1>;
	};
};
#include "versal2-vek385-reva.dtsi"
